// *************************************************************************** *
// *                                                                           *
// *                      Mentor Graphics Corporation                          *
// *                          All rights reserved                              *
// *                                                                           *
// *************************************************************************** *
// *                                                                           *
// * Description:         CANDB File                                           *
// * Generated at:        2021-02-26 13:32                                     *
// * System:              SPA4710_Final2                                       *
// * Variant:             ConfigurationsSPA3AD                                 *
// * Network:             Mid3Can                                              *
// *                                                                           *
// *************************************************************************** *
// *                                                                           *
// *             THIS CONFIGURATION MIGHT CONTAIN SOME ERRORS                  *
// *              IF THE INPUT MODEL WAS NOT PROPERLY FORMED!                  *
// *                    Do Not Use this File directly!                         *
// *                                                                           *
// *************************************************************************** *
VERSION "Mid3Can"

NS_ :

BS_ :

BU_ :  ETC SSM VCU1 VIM VIMB

BO_ 1120 VCU1Mid3CanFr14 : 8 VCU1
 SG_ CllsnAidSnvtySeld_UB : 20|1@0+ (1,0) [0|1] "" VIM,VIMB
 SG_ CllsnAidSnvtySeldPen : 35|4@0+ (1,0) [0|15] "" VIM,VIMB
 SG_ CllsnAidSnvtySeldSts : 37|2@0+ (1,0) [0|3] "" VIM,VIMB
 SG_ CllsnFwdWarnReq : 45|1@0+ (1,0) [0|1] "" VIM,VIMB
 SG_ CllsnFwdWarnReq_UB : 46|1@0+ (1,0) [0|1] "" VIM,VIMB
 SG_ CllsnThreat : 39|2@0+ (1,0) [0|3] "" VIM,VIMB
 SG_ CllsnThreat_UB : 47|1@0+ (1,0) [0|1] "" VIM,VIMB
 SG_ CnclReqForCrsCtrl : 22|2@0+ (1,0) [0|3] "" VIM,VIMB
 SG_ CnclReqForCrsCtrl_UB : 23|1@0+ (1,0) [0|1] "" VIM,VIMB
 SG_ CooltFlowInDtElecForExt : 1|10@0+ (0.01,0.0) [0.0|10.23] "L / min" VIM,VIMB
 SG_ CooltFlowInDtElecForExt_UB : 2|1@0+ (1,0) [0|1] "" VIM,VIMB
 SG_ CooltTInDtElecForExt : 18|11@0+ (0.1,-40.0) [-40.0|140.0] "degC" VIM,VIMB
 SG_ CooltTInDtElecForExt_UB : 3|1@0+ (1,0) [0|1] "" VIM,VIMB
 SG_ IndcrDisp1WdSts : 5|2@0+ (1,0) [0|3] "" VIM,VIMB
 SG_ IndcrDisp1WdSts_UB : 6|1@0+ (1,0) [0|1] "" VIM,VIMB
 SG_ IndcrTurnSts1WdSts : 43|2@0+ (1,0) [0|3] "" VIM
 SG_ IndcrTurnSts1WdSts_UB : 44|1@0+ (1,0) [0|1] "" VIM
 SG_ SrvRqrdForCllsnAid : 19|1@0+ (1,0) [0|1] "" VIM,VIMB
 SG_ SrvRqrdForCllsnAid_UB : 7|1@0+ (1,0) [0|1] "" VIM,VIMB

BO_ 1084 VCU1Mid3CanFr15 : 8 VCU1
 SG_ BeamHiIndcnDisp : 10|1@0+ (1,0) [0|1] "" VIM,VIMB
 SG_ BeamHiIndcnDisp_UB : 11|1@0+ (1,0) [0|1] "" VIM,VIMB
 SG_ BltLockStAtRowSecMid_UB : 3|1@0+ (1,0) [0|1] "" VIM,VIMB
 SG_ BltLockStAtRowSecMidForBltLockEquid : 2|1@0+ (1,0) [0|1] "" VIM,VIMB
 SG_ BltLockStAtRowSecMidForBltLockSt1 : 1|1@0+ (1,0) [0|1] "" VIM,VIMB
 SG_ BltLockStAtRowSecMidForBltLockSts : 0|1@0+ (1,0) [0|1] "" VIM,VIMB
 SG_ FltIndcrTurnLeFrnt : 24|1@0+ (1,0) [0|1] "" VIM,VIMB
 SG_ FltIndcrTurnLeFrnt_UB : 25|1@0+ (1,0) [0|1] "" VIM,VIMB
 SG_ FltIndcrTurnLeRe : 38|1@0+ (1,0) [0|1] "" VIM,VIMB
 SG_ FltIndcrTurnLeRe_UB : 39|1@0+ (1,0) [0|1] "" VIM,VIMB
 SG_ FltIndcrTurnRiFrnt : 36|1@0+ (1,0) [0|1] "" VIM,VIMB
 SG_ FltIndcrTurnRiFrnt_UB : 37|1@0+ (1,0) [0|1] "" VIM,VIMB
 SG_ FltIndcrTurnRiRe : 34|1@0+ (1,0) [0|1] "" VIM,VIMB
 SG_ FltIndcrTurnRiRe_UB : 35|1@0+ (1,0) [0|1] "" VIM,VIMB
 SG_ FltLiRvsg : 60|1@0+ (1,0) [0|1] "" VIM,VIMB
 SG_ FltLiRvsg_UB : 61|1@0+ (1,0) [0|1] "" VIM,VIMB
 SG_ FltOfBeamHiLe : 42|1@0+ (1,0) [0|1] "" VIM,VIMB
 SG_ FltOfBeamHiLe_UB : 43|1@0+ (1,0) [0|1] "" VIM,VIMB
 SG_ FltOfBeamHiRi : 40|1@0+ (1,0) [0|1] "" VIM,VIMB
 SG_ FltOfBeamHiRi_UB : 41|1@0+ (1,0) [0|1] "" VIM,VIMB
 SG_ FltOfBeamLoLe : 54|1@0+ (1,0) [0|1] "" VIM,VIMB
 SG_ FltOfBeamLoLe_UB : 55|1@0+ (1,0) [0|1] "" VIM,VIMB
 SG_ FltOfBeamLoRi : 52|1@0+ (1,0) [0|1] "" VIM,VIMB
 SG_ FltOfBeamLoRi_UB : 53|1@0+ (1,0) [0|1] "" VIM,VIMB
 SG_ FltOfBrkLiHiMntd : 30|1@0+ (1,0) [0|1] "" VIM,VIMB
 SG_ FltOfBrkLiHiMntd_UB : 31|1@0+ (1,0) [0|1] "" VIM,VIMB
 SG_ FltOfBrkLiLe : 28|1@0+ (1,0) [0|1] "" VIM,VIMB
 SG_ FltOfBrkLiLe_UB : 29|1@0+ (1,0) [0|1] "" VIM,VIMB
 SG_ FltOfBrkLiRi : 26|1@0+ (1,0) [0|1] "" VIM,VIMB
 SG_ FltOfBrkLiRi_UB : 27|1@0+ (1,0) [0|1] "" VIM,VIMB
 SG_ FltOfFogLiFrnt : 44|1@0+ (1,0) [0|1] "" VIM,VIMB
 SG_ FltOfFogLiFrnt_UB : 45|1@0+ (1,0) [0|1] "" VIM,VIMB
 SG_ FltOfLiPosnFrntLe : 32|1@0+ (1,0) [0|1] "" VIM,VIMB
 SG_ FltOfLiPosnFrntLe_UB : 33|1@0+ (1,0) [0|1] "" VIM,VIMB
 SG_ FltOfLiPosnFrntRi : 46|1@0+ (1,0) [0|1] "" VIM,VIMB
 SG_ FltOfLiPosnFrntRi_UB : 47|1@0+ (1,0) [0|1] "" VIM,VIMB
 SG_ FltOfPlateNr : 62|1@0+ (1,0) [0|1] "" VIM,VIMB
 SG_ FltOfPlateNr_UB : 63|1@0+ (1,0) [0|1] "" VIM,VIMB
 SG_ FltOfPosnReLe : 50|1@0+ (1,0) [0|1] "" VIM,VIMB
 SG_ FltOfPosnReLe_UB : 51|1@0+ (1,0) [0|1] "" VIM,VIMB
 SG_ FltOfPosnReRi : 48|1@0+ (1,0) [0|1] "" VIM,VIMB
 SG_ FltOfPosnReRi_UB : 49|1@0+ (1,0) [0|1] "" VIM,VIMB
 SG_ HdlampSysFailr : 58|1@0+ (1,0) [0|1] "" VIM,VIMB
 SG_ HdlampSysFailr_UB : 59|1@0+ (1,0) [0|1] "" VIM,VIMB
 SG_ SysBrkLiFailr : 12|1@0+ (1,0) [0|1] "" VIM,VIMB
 SG_ SysBrkLiFailr_UB : 13|1@0+ (1,0) [0|1] "" VIM,VIMB
 SG_ SysDirIndcnFailr : 14|1@0+ (1,0) [0|1] "" VIM,VIMB
 SG_ SysDirIndcnFailr_UB : 15|1@0+ (1,0) [0|1] "" VIM,VIMB
 SG_ TireRdEstimd : 9|10@0+ (0.00048828,0.25) [0.25|0.50048764] "m" SSM
 SG_ TireRdEstimd_UB : 4|1@0+ (1,0) [0|1] "" SSM
 SG_ TireRdEstimdQly : 6|2@0+ (1,0) [0|3] "" SSM
 SG_ TireRdEstimdQly_UB : 7|1@0+ (1,0) [0|1] "" SSM

BO_ 512 VCU1Mid3CanFr16 : 8 VCU1
 SG_ AsySftyDecelEnadByVehDyn : 62|1@0+ (1,0) [0|1] "" VIM,VIMB
 SG_ AsySftyDecelEnadByVehDyn_UB : 63|1@0+ (1,0) [0|1] "" VIM,VIMB
 SG_ EngOilPWarn : 5|1@0+ (1,0) [0|1] "" VIM,VIMB
 SG_ EngOilPWarn_UB : 6|1@0+ (1,0) [0|1] "" VIM,VIMB
 SG_ InhbOfAsySftyDecelByVehDyn : 60|1@0+ (1,0) [0|1] "" VIM,VIMB
 SG_ InhbOfAsySftyDecelByVehDyn_UB : 61|1@0+ (1,0) [0|1] "" VIM,VIMB
 SG_ PrpsnErrIndcnReq : 49|2@0+ (1,0) [0|3] "" VIM,VIMB
 SG_ PrpsnErrIndcnReq_UB : 7|1@0+ (1,0) [0|1] "" VIM,VIMB
 SG_ RoadLoadNom_UB : 4|1@0+ (1,0) [0|1] "" SSM
 SG_ RoadLoadNomCoeff0 : 2|11@0+ (1.0,0.0) [0.0|2047.0] "N" SSM
 SG_ RoadLoadNomCoeff1 : 17|10@0- (0.05859,0.0) [-29.8809|29.939490000000003] "Ns/m" SSM
 SG_ RoadLoadNomCoeff2 : 33|10@0+ (0.002929,0.0) [0.0|2.902639] "Ns^2/m^2" SSM
 SG_ RoadLoadNomCoeffSts : 3|1@0+ (1,0) [0|1] "" SSM
 SG_ TankFlapSts : 57|2@0+ (1,0) [0|3] "" VIM,VIMB
 SG_ TankFlapSts_UB : 58|1@0+ (1,0) [0|1] "" VIM,VIMB
 SG_ TrsmFltIndcn : 54|5@0+ (1,0) [0|31] "" VIM,VIMB
 SG_ TrsmFltIndcn_UB : 55|1@0+ (1,0) [0|1] "" VIM,VIMB

BO_ 384 VCU1Mid3CanFr17 : 8 VCU1
 SG_ ALnchTiDly3_UB : 47|1@0+ (1,0) [0|1] "" VIM,VIMB
 SG_ ALnchTiDly3Qf : 39|2@0+ (1,0) [0|3] "" VIM,VIMB
 SG_ ALnchTiDly3Sec2 : 37|6@0+ (0.1,0.0) [0.0|6.0] "s" VIM,VIMB
 SG_ AlrmSt : 9|2@0+ (1,0) [0|3] "" VIM,VIMB
 SG_ AlrmSts1_UB : 1|1@0+ (1,0) [0|1] "" VIM,VIMB
 SG_ AlrmTrgSrc : 13|4@0+ (1,0) [0|15] "" VIM,VIMB
 SG_ DoorDrvrReSts : 17|2@0+ (1,0) [0|3] "" SSM,VIM,VIMB
 SG_ DoorDrvrReSts_UB : 18|1@0+ (1,0) [0|1] "" SSM,VIM,VIMB
 SG_ DoorDrvrSts : 20|2@0+ (1,0) [0|3] "" SSM,VIM,VIMB
 SG_ DoorDrvrSts_UB : 21|1@0+ (1,0) [0|1] "" SSM,VIM,VIMB
 SG_ DoorPassReSts : 31|2@0+ (1,0) [0|3] "" SSM,VIM,VIMB
 SG_ DoorPassReSts_UB : 22|1@0+ (1,0) [0|1] "" SSM,VIM,VIMB
 SG_ DoorPassSts : 29|2@0+ (1,0) [0|3] "" SSM,VIM,VIMB
 SG_ DoorPassSts_UB : 23|1@0+ (1,0) [0|1] "" SSM,VIM,VIMB
 SG_ EngOilLvlSts : 7|3@0+ (1,0) [0|7] "" VIM,VIMB
 SG_ EngOilLvlSts_UB : 4|1@0+ (1,0) [0|1] "" VIM,VIMB
 SG_ HoodSts : 27|2@0+ (1,0) [0|3] "" VIM,VIMB
 SG_ HoodSts_UB : 2|1@0+ (1,0) [0|1] "" VIM,VIMB
 SG_ SnsrInclnFailr : 14|1@0+ (1,0) [0|1] "" VIM,VIMB
 SG_ SnsrIntrScanrFailr : 15|1@0+ (1,0) [0|1] "" VIM,VIMB
 SG_ SnsrSoundrBattBackedFailr : 0|1@0+ (1,0) [0|1] "" VIM,VIMB
 SG_ TrSts : 25|2@0+ (1,0) [0|3] "" SSM,VIM,VIMB
 SG_ TrSts_UB : 3|1@0+ (1,0) [0|1] "" SSM,VIM,VIMB

BO_ 119 VCU1Mid3CanFr18 : 8 VCU1
 SG_ AccrPedlPsd_UB : 9|1@0+ (1,0) [0|1] "" VIM,VIMB
 SG_ AccrPedlPsdAccrPedlPsd : 11|1@0+ (1,0) [0|1] "" VIM,VIMB
 SG_ AccrPedlPsdAccrPedlPsdChks : 7|8@0+ (1.0,0.0) [0.0|255.0] "Unitless" VIM,VIMB
 SG_ AccrPedlPsdAccrPedlPsdCntr : 15|4@0+ (1.0,0.0) [0.0|15.0] "Unitless" VIM,VIMB
 SG_ AccrPedlPsdAccrPedlPsdSts : 10|1@0+ (1,0) [0|1] "" VIM,VIMB
 SG_ AsySftyBrkDlyEstimd : 22|7@0+ (0.01,0.0) [0.0|1.27] "s" VIM,VIMB
 SG_ AsySftyBrkDlyEstimd_UB : 23|1@0+ (1,0) [0|1] "" VIM,VIMB
 SG_ BrkPedlNotPsdSafe : 31|1@0+ (1,0) [0|1] "" VIM,VIMB
 SG_ BrkPedlPsd : 30|1@0+ (1,0) [0|1] "" VIM,VIMB
 SG_ BrkPedlPsdChks : 39|8@0+ (1.0,0.0) [0.0|255.0] "Unitless" VIM,VIMB
 SG_ BrkPedlPsdCntr : 27|4@0+ (1.0,0.0) [0.0|15.0] "Unitless" VIM,VIMB
 SG_ BrkPedlPsdQf : 29|2@0+ (1,0) [0|3] "" VIM,VIMB
 SG_ BrkPedlPsdSafeGroup_UB : 8|1@0+ (1,0) [0|1] "" VIM,VIMB
 SG_ HvSysActvStsExt1 : 46|1@0+ (1,0) [0|1] "" VIM,VIMB
 SG_ HvSysActvStsExt1_UB : 47|1@0+ (1,0) [0|1] "" VIM,VIMB
 SG_ OvrdDecelByDrvr_UB : 45|1@0+ (1,0) [0|1] "" VIM,VIMB
 SG_ OvrdDecelByDrvrOvrdDecelByDrvr : 44|1@0+ (1,0) [0|1] "" VIM,VIMB
 SG_ OvrdDecelByDrvrOvrdDecelByDrvrChks : 55|8@0+ (1.0,0.0) [0.0|255.0] "Unitless" VIM,VIMB
 SG_ OvrdDecelByDrvrOvrdDecelByDrvrCntr : 43|4@0+ (1.0,0.0) [0.0|15.0] "Unitless" VIM,VIMB

BO_ 104 VCU1Mid3CanFr19 : 8 VCU1
 SG_ AccrPedlRat : 6|15@0+ (0.00390625,0.0) [0.0|100.0] "%" VIM,VIMB
 SG_ AccrPedlRat_UB : 7|1@0+ (1,0) [0|1] "" VIM,VIMB
 SG_ ChrgnUReqExt : 31|8@0+ (0.025,10.6) [10.6|16.0] "Volt" VIM,VIMB
 SG_ ChrgnUReqExt_UB : 59|1@0+ (1,0) [0|1] "" VIM,VIMB
 SG_ DrvrDecelReq : 23|8@0- (0.1,0.0) [-12.8|12.700000000000001] "m/s^2" VIM,VIMB
 SG_ DrvrDecelReq_UB : 32|1@0+ (1,0) [0|1] "" VIM,VIMB
 SG_ PtGearAct : 46|4@0+ (1,0) [0|15] "" VIM,VIMB
 SG_ PtGearAct_UB : 47|1@0+ (1,0) [0|1] "" VIM,VIMB
 SG_ TirePWarnFrntRi_UB : 42|1@0+ (1,0) [0|1] "" VIM,VIMB
 SG_ TirePWarnFrntRiTirePWarn : 55|2@0+ (1,0) [0|3] "" VIM,VIMB
 SG_ TirePWarnFrntRiTirePWarnType : 53|2@0+ (1,0) [0|3] "" VIM,VIMB
 SG_ TirePWarnReLe_UB : 41|1@0+ (1,0) [0|1] "" VIM,VIMB
 SG_ TirePWarnReLeTirePWarn : 51|2@0+ (1,0) [0|3] "" VIM,VIMB
 SG_ TirePWarnReLeTirePWarnType : 49|2@0+ (1,0) [0|3] "" VIM,VIMB
 SG_ TirePWarnReRi_UB : 40|1@0+ (1,0) [0|1] "" VIM,VIMB
 SG_ TirePWarnReRiTirePWarn : 63|2@0+ (1,0) [0|3] "" VIM,VIMB
 SG_ TirePWarnReRiTirePWarnType : 61|2@0+ (1,0) [0|3] "" VIM,VIMB

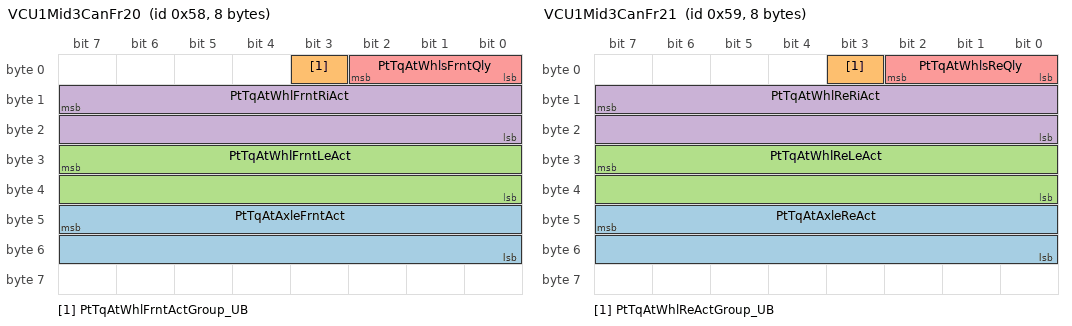
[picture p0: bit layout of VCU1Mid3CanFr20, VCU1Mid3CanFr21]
BO_ 88 VCU1Mid3CanFr20 : 8 VCU1
 SG_ PtTqAtAxleFrntAct : 47|16@0- (1.0,0.0) [-20000.0|20000.0] "NewtonMeter" VIM,VIMB
 SG_ PtTqAtWhlFrntActGroup_UB : 3|1@0+ (1,0) [0|1] "" VIM,VIMB
 SG_ PtTqAtWhlFrntLeAct : 31|16@0- (1.0,0.0) [-20000.0|20000.0] "NewtonMeter" VIM,VIMB
 SG_ PtTqAtWhlFrntRiAct : 15|16@0- (1.0,0.0) [-20000.0|20000.0] "NewtonMeter" VIM,VIMB
 SG_ PtTqAtWhlsFrntQly : 2|3@0+ (1,0) [0|7] "" VIM,VIMB

BO_ 89 VCU1Mid3CanFr21 : 8 VCU1
 SG_ PtTqAtAxleReAct : 47|16@0- (1.0,0.0) [-20000.0|20000.0] "NewtonMeter" VIM,VIMB
 SG_ PtTqAtWhlReActGroup_UB : 3|1@0+ (1,0) [0|1] "" VIM,VIMB
 SG_ PtTqAtWhlReLeAct : 31|16@0- (1.0,0.0) [-20000.0|20000.0] "NewtonMeter" VIM,VIMB
 SG_ PtTqAtWhlReRiAct : 15|16@0- (1.0,0.0) [-20000.0|20000.0] "NewtonMeter" VIM,VIMB
 SG_ PtTqAtWhlsReQly : 2|3@0+ (1,0) [0|7] "" VIM,VIMB

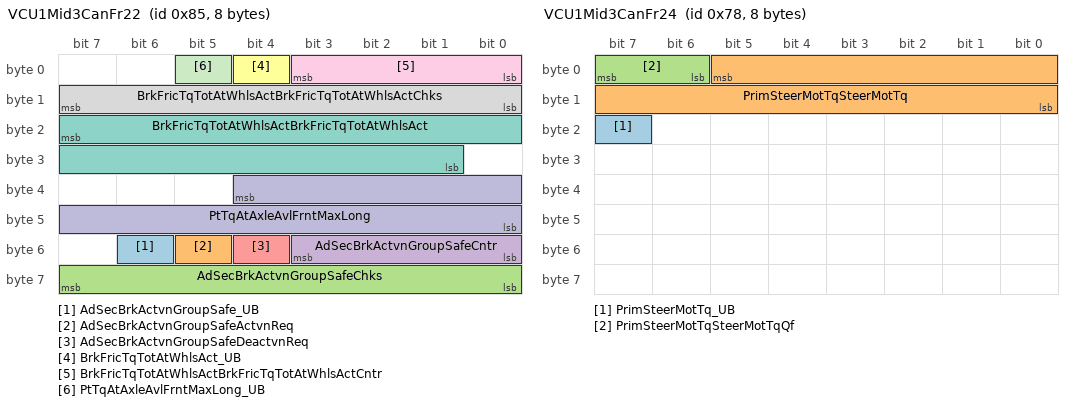
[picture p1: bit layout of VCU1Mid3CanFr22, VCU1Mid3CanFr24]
BO_ 133 VCU1Mid3CanFr22 : 8 VCU1
 SG_ AdSecBrkActvnGroupSafe_UB : 54|1@0+ (1,0) [0|1] "" SSM
 SG_ AdSecBrkActvnGroupSafeActvnReq : 53|1@0+ (1,0) [0|1] "" SSM
 SG_ AdSecBrkActvnGroupSafeChks : 63|8@0+ (1.0,0.0) [0.0|255.0] "Unitless" SSM
 SG_ AdSecBrkActvnGroupSafeCntr : 51|4@0+ (1.0,0.0) [0.0|15.0] "Unitless" SSM
 SG_ AdSecBrkActvnGroupSafeDeactvnReq : 52|1@0+ (1,0) [0|1] "" SSM
 SG_ BrkFricTqTotAtWhlsAct_UB : 4|1@0+ (1,0) [0|1] "" VIM,VIMB
 SG_ BrkFricTqTotAtWhlsActBrkFricTqTotAtWhlsAct : 23|15@0+ (1.0,0.0) [0.0|20000.0] "NewtonMeter" VIM,VIMB
 SG_ BrkFricTqTotAtWhlsActBrkFricTqTotAtWhlsActChks : 15|8@0+ (1.0,0.0) [0.0|255.0] "Unitless" VIM,VIMB
 SG_ BrkFricTqTotAtWhlsActBrkFricTqTotAtWhlsActCntr : 3|4@0+ (1.0,0.0) [0.0|15.0] "Unitless" VIM,VIMB
 SG_ PtTqAtAxleAvlFrntMaxLong : 36|13@0- (4.0,0.0) [-16384.0|16380.0] "NewtonMeter" VIM,VIMB
 SG_ PtTqAtAxleAvlFrntMaxLong_UB : 5|1@0+ (1,0) [0|1] "" VIM,VIMB

BO_ 352 VCU1Mid3CanFr23 : 8 VCU1
 SG_ TirePMonSysFlt : 6|3@0+ (1,0) [0|7] "" VIM,VIMB
 SG_ TirePMonSysFlt_UB : 7|1@0+ (1,0) [0|1] "" VIM,VIMB
 SG_ TirePValFrntLe_UB : 3|1@0+ (1,0) [0|1] "" SSM,VIM,VIMB
 SG_ TirePValFrntLeTirepabsltVal1 : 15|8@0+ (2.5,0.0) [0.0|637.5] "hPa" SSM,VIM,VIMB
 SG_ TirePValFrntLeTirePabsltValQF : 1|2@0+ (1,0) [0|3] "" SSM,VIM,VIMB
 SG_ TirePValFrntLeTirePPosn : 2|1@0+ (1,0) [0|1] "" SSM,VIM,VIMB
 SG_ TirePValFrntRi_UB : 19|1@0+ (1,0) [0|1] "" SSM,VIM,VIMB
 SG_ TirePValFrntRiTirePAbsltVal1 : 31|8@0+ (2.5,0.0) [0.0|637.5] "hPa" SSM,VIM,VIMB
 SG_ TirePValFrntRiTirePAbsltValQF : 17|2@0+ (1,0) [0|3] "" SSM,VIM,VIMB
 SG_ TirePValFrntRiTirePPosn : 18|1@0+ (1,0) [0|1] "" SSM,VIM,VIMB
 SG_ TirePValReLe_UB : 20|1@0+ (1,0) [0|1] "" SSM,VIM,VIMB
 SG_ TirePValReLeTirePAbsltVal1 : 47|8@0+ (2.5,0.0) [0.0|637.5] "hPa" SSM,VIM,VIMB
 SG_ TirePValReLeTirePAbsltValQF : 33|2@0+ (1,0) [0|3] "" SSM,VIM,VIMB
 SG_ TirePValReLeTirePPosn : 34|1@0+ (1,0) [0|1] "" SSM,VIM,VIMB
 SG_ TirePValReRi_UB : 21|1@0+ (1,0) [0|1] "" SSM,VIM,VIMB
 SG_ TirePValReRiTirePAbsltVal1 : 63|8@0+ (2.5,0.0) [0.0|637.5] "hPa" SSM,VIM,VIMB
 SG_ TirePValReRiTirePAbsltValQF : 49|2@0+ (1,0) [0|3] "" SSM,VIM,VIMB
 SG_ TirePValReRiTirePPosn : 50|1@0+ (1,0) [0|1] "" SSM,VIM,VIMB
 SG_ TirePWarnCmn_UB : 39|1@0+ (1,0) [0|1] "" VIM,VIMB
 SG_ TirePWarnCmnTirePWarn : 38|2@0+ (1,0) [0|3] "" VIM,VIMB
 SG_ TirePWarnCmnTirePWarnType : 36|2@0+ (1,0) [0|3] "" VIM,VIMB
 SG_ TirePWarnFrntLe_UB : 55|1@0+ (1,0) [0|1] "" VIM,VIMB
 SG_ TirePWarnFrntLeTirePWarn : 54|2@0+ (1,0) [0|3] "" VIM,VIMB
 SG_ TirePWarnFrntLeTirePWarnType : 52|2@0+ (1,0) [0|3] "" VIM,VIMB

BO_ 120 VCU1Mid3CanFr24 : 8 VCU1
 SG_ PrimSteerMotTq_UB : 23|1@0+ (1,0) [0|1] "" VIM
 SG_ PrimSteerMotTqSteerMotTq : 5|14@0- (0.00390625,0.0) [-30.0|30.0] "NewtonMeter" VIM
 SG_ PrimSteerMotTqSteerMotTqQf : 7|2@0+ (1,0) [0|3] "" VIM

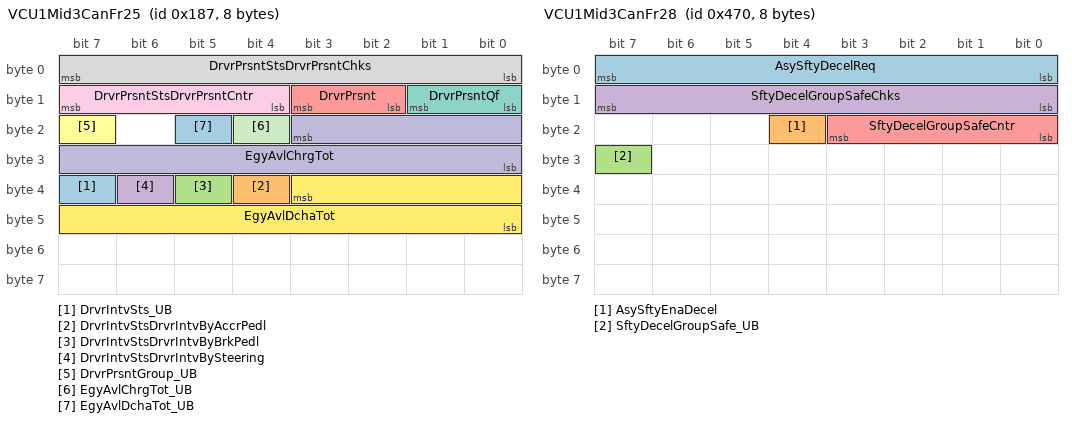
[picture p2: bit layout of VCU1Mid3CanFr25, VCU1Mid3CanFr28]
BO_ 391 VCU1Mid3CanFr25 : 8 VCU1
 SG_ DrvrIntvSts_UB : 39|1@0+ (1,0) [0|1] "" VIM,VIMB
 SG_ DrvrIntvStsDrvrIntvByAccrPedl : 36|1@0+ (1,0) [0|1] "" VIM,VIMB
 SG_ DrvrIntvStsDrvrIntvByBrkPedl : 37|1@0+ (1,0) [0|1] "" VIM,VIMB
 SG_ DrvrIntvStsDrvrIntvBySteering : 38|1@0+ (1,0) [0|1] "" VIM,VIMB
 SG_ DrvrPrsnt : 11|2@0+ (1,0) [0|3] "" VIM,VIMB
 SG_ DrvrPrsntGroup_UB : 23|1@0+ (1,0) [0|1] "" VIM,VIMB
 SG_ DrvrPrsntQf : 9|2@0+ (1,0) [0|3] "" VIM,VIMB
 SG_ DrvrPrsntStsDrvrPrsntChks : 7|8@0+ (1.0,0.0) [0.0|255.0] "Unitless" VIM,VIMB
 SG_ DrvrPrsntStsDrvrPrsntCntr : 15|4@0+ (1.0,0.0) [0.0|15.0] "Unitless" VIM,VIMB
 SG_ EgyAvlChrgTot : 19|12@0+ (50.0,-500.0) [-500.0|120000.0] "Wh" VIM,VIMB
 SG_ EgyAvlChrgTot_UB : 20|1@0+ (1,0) [0|1] "" VIM,VIMB
 SG_ EgyAvlDchaTot : 35|12@0+ (50.0,-500.0) [-500.0|120000.0] "Wh" VIM,VIMB
 SG_ EgyAvlDchaTot_UB : 21|1@0+ (1,0) [0|1] "" VIM,VIMB

BO_ 1136 VCU1Mid3CanFr28 : 8 VCU1
 SG_ AsySftyDecelReq : 7|8@0+ (0.1,0.0) [0.0|15.0] "Unitless" VIM,VIMB
 SG_ AsySftyEnaDecel : 20|1@0+ (1,0) [0|1] "" VIM,VIMB
 SG_ SftyDecelGroupSafe_UB : 31|1@0+ (1,0) [0|1] "" VIM,VIMB
 SG_ SftyDecelGroupSafeChks : 15|8@0+ (1.0,0.0) [0.0|255.0] "Unitless" VIM,VIMB
 SG_ SftyDecelGroupSafeCntr : 19|4@0+ (1.0,0.0) [0.0|15.0] "Unitless" VIM,VIMB

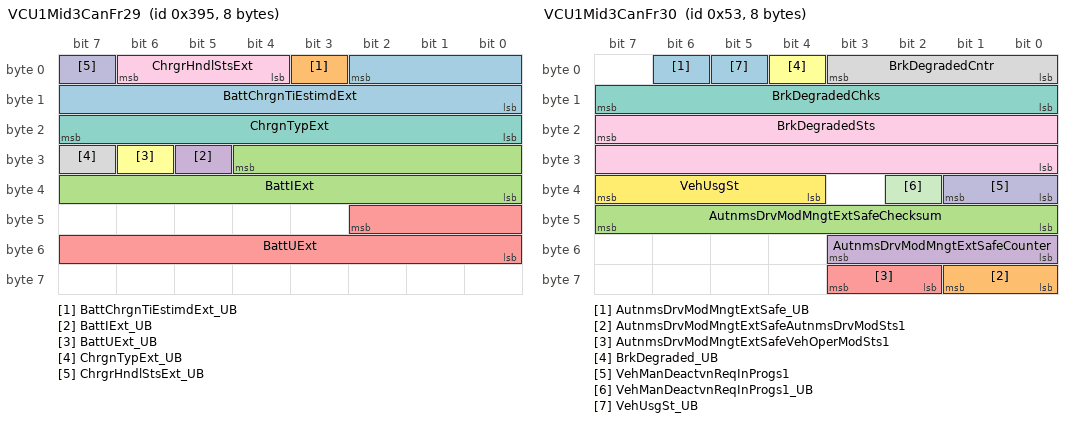
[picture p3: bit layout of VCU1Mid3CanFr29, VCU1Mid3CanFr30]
BO_ 917 VCU1Mid3CanFr29 : 8 VCU1
 SG_ BattChrgnTiEstimdExt : 2|11@0+ (1.0,0.0) [0.0|2047.0] "Mins" VIM,VIMB
 SG_ BattChrgnTiEstimdExt_UB : 3|1@0+ (1,0) [0|1] "" VIM,VIMB
 SG_ BattIExt : 28|13@0+ (0.1,-410.0) [-410.0|409.1] "A" VIM,VIMB
 SG_ BattIExt_UB : 29|1@0+ (1,0) [0|1] "" VIM,VIMB
 SG_ BattUExt : 42|11@0+ (0.25,0.0) [0.0|511.0] "Volt" VIM,VIMB
 SG_ BattUExt_UB : 30|1@0+ (1,0) [0|1] "" VIM,VIMB
 SG_ ChrgnTypExt : 23|8@0+ (1,0) [0|255] "" VIM,VIMB
 SG_ ChrgnTypExt_UB : 31|1@0+ (1,0) [0|1] "" VIM,VIMB
 SG_ ChrgrHndlStsExt : 6|3@0+ (1,0) [0|7] "" VIM,VIMB
 SG_ ChrgrHndlStsExt_UB : 7|1@0+ (1,0) [0|1] "" VIM,VIMB

BO_ 83 VCU1Mid3CanFr30 : 8 VCU1
 SG_ AutnmsDrvModMngtExtSafe_UB : 6|1@0+ (1,0) [0|1] "" VIM,VIMB
 SG_ AutnmsDrvModMngtExtSafeAutnmsDrvModSts1 : 56|2@1+ (1,0) [0|3] "" VIM,VIMB
 SG_ AutnmsDrvModMngtExtSafeChecksum : 40|8@1+ (1.0,0.0) [0.0|255.0] "Unitless" VIM,VIMB
 SG_ AutnmsDrvModMngtExtSafeCounter : 48|4@1+ (1.0,0.0) [0.0|15.0] "Unitless" VIM,VIMB
 SG_ AutnmsDrvModMngtExtSafeVehOperModSts1 : 58|2@1+ (1,0) [0|3] "" VIM,VIMB
 SG_ BrkDegraded_UB : 4|1@0+ (1,0) [0|1] "" VIM,VIMB
 SG_ BrkDegradedChks : 15|8@0+ (1.0,0.0) [0.0|255.0] "Unitless" VIM,VIMB
 SG_ BrkDegradedCntr : 3|4@0+ (1.0,0.0) [0.0|15.0] "Unitless" VIM,VIMB
 SG_ BrkDegradedSts : 23|16@0+ (1.0,0.0) [0.0|65535.0] "Unitless" VIM,VIMB
 SG_ VehManDeactvnReqInProgs1 : 33|2@0+ (1,0) [0|3] "" VIM,VIMB
 SG_ VehManDeactvnReqInProgs1_UB : 34|1@0+ (1,0) [0|1] "" VIM,VIMB
 SG_ VehUsgSt : 39|4@0+ (1,0) [0|15] "" VIM,VIMB
 SG_ VehUsgSt_UB : 5|1@0+ (1,0) [0|1] "" VIM,VIMB

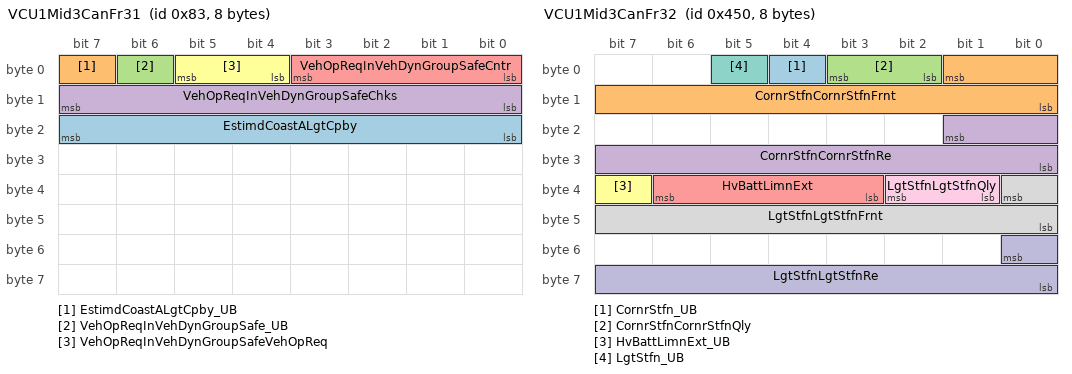
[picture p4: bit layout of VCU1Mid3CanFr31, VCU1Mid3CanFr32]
BO_ 131 VCU1Mid3CanFr31 : 8 VCU1
 SG_ EstimdCoastALgtCpby : 23|8@0+ (0.1,-3.0) [-3.0|15.0] "m/s^2" VIM,VIMB
 SG_ EstimdCoastALgtCpby_UB : 7|1@0+ (1,0) [0|1] "" VIM,VIMB
 SG_ VehOpReqInVehDynGroupSafe_UB : 6|1@0+ (1,0) [0|1] "" SSM
 SG_ VehOpReqInVehDynGroupSafeChks : 15|8@0+ (1.0,0.0) [0.0|255.0] "Unitless" SSM
 SG_ VehOpReqInVehDynGroupSafeCntr : 3|4@0+ (1.0,0.0) [0.0|15.0] "Unitless" SSM
 SG_ VehOpReqInVehDynGroupSafeVehOpReq : 5|2@0+ (1,0) [0|3] "" SSM

BO_ 1104 VCU1Mid3CanFr32 : 8 VCU1
 SG_ CornrStfn_UB : 4|1@0+ (1,0) [0|1] "" SSM
 SG_ CornrStfnCornrStfnFrnt : 1|10@0+ (390.625,0.0) [0.0|399609.375] "N" SSM
 SG_ CornrStfnCornrStfnQly : 3|2@0+ (1,0) [0|3] "" SSM
 SG_ CornrStfnCornrStfnRe : 17|10@0+ (390.625,0.0) [0.0|399609.375] "N" SSM
 SG_ HvBattLimnExt : 38|4@0+ (1,0) [0|15] "" VIM
 SG_ HvBattLimnExt_UB : 39|1@0+ (1,0) [0|1] "" VIM
 SG_ LgtStfn_UB : 5|1@0+ (1,0) [0|1] "" SSM
 SG_ LgtStfnLgtStfnFrnt : 32|9@0+ (0.5,0.0) [0.0|255.5] "Unitless" SSM
 SG_ LgtStfnLgtStfnQly : 34|2@0+ (1,0) [0|3] "" SSM
 SG_ LgtStfnLgtStfnRe : 48|9@0+ (0.5,0.0) [0.0|255.5] "Unitless" SSM

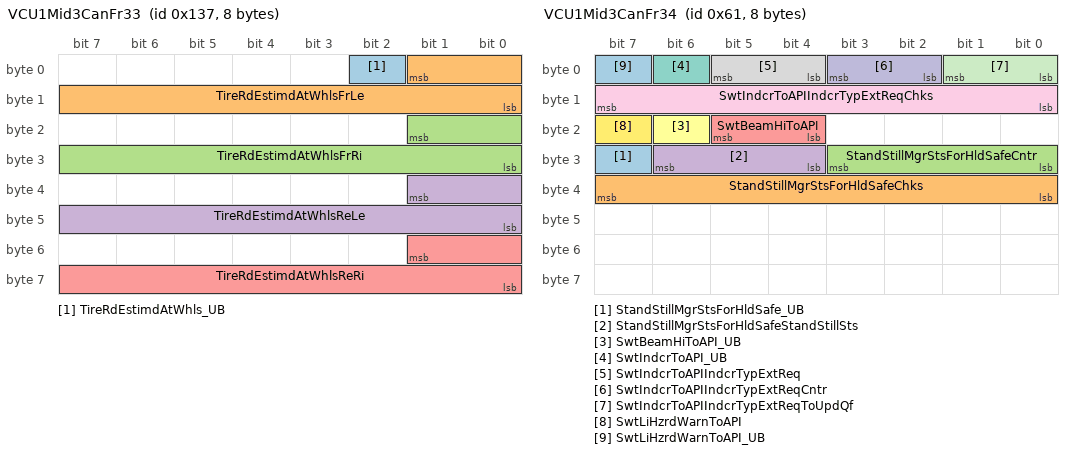
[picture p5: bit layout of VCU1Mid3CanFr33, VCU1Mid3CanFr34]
BO_ 311 VCU1Mid3CanFr33 : 8 VCU1
 SG_ TireRdEstimdAtWhls_UB : 2|1@0+ (1,0) [0|1] "" SSM
 SG_ TireRdEstimdAtWhlsFrLe : 1|10@0+ (0.00048828,0.25) [0.25|0.50048764] "m" SSM
 SG_ TireRdEstimdAtWhlsFrRi : 17|10@0+ (0.00048828,0.25) [0.25|0.50048764] "m" SSM
 SG_ TireRdEstimdAtWhlsReLe : 33|10@0+ (0.00048828,0.25) [0.25|0.50048764] "m" SSM
 SG_ TireRdEstimdAtWhlsReRi : 49|10@0+ (0.00048828,0.25) [0.25|0.50048764] "m" SSM

BO_ 97 VCU1Mid3CanFr34 : 8 VCU1
 SG_ StandStillMgrStsForHldSafe_UB : 31|1@0+ (1,0) [0|1] "" VIM,VIMB
 SG_ StandStillMgrStsForHldSafeChks : 39|8@0+ (1.0,0.0) [0.0|255.0] "Unitless" VIM,VIMB
 SG_ StandStillMgrStsForHldSafeCntr : 27|4@0+ (1.0,0.0) [0.0|15.0] "Unitless" VIM,VIMB
 SG_ StandStillMgrStsForHldSafeStandStillSts : 30|3@0+ (1,0) [0|7] "" VIM,VIMB
 SG_ SwtBeamHiToAPI : 21|2@0+ (1,0) [0|3] "" VIM,VIMB
 SG_ SwtBeamHiToAPI_UB : 22|1@0+ (1,0) [0|1] "" VIM,VIMB
 SG_ SwtIndcrToAPI_UB : 6|1@0+ (1,0) [0|1] "" VIM,VIMB
 SG_ SwtIndcrToAPIIndcrTypExtReq : 5|2@0+ (1,0) [0|3] "" VIM,VIMB
 SG_ SwtIndcrToAPIIndcrTypExtReqChks : 15|8@0+ (1.0,0.0) [0.0|255.0] "Unitless" VIM,VIMB
 SG_ SwtIndcrToAPIIndcrTypExtReqCntr : 3|2@0+ (1.0,0.0) [0.0|3.0] "Unitless" VIM,VIMB
 SG_ SwtIndcrToAPIIndcrTypExtReqToUpdQf : 1|2@0+ (1,0) [0|3] "" VIM,VIMB
 SG_ SwtLiHzrdWarnToAPI : 23|1@0+ (1,0) [0|1] "" VIM,VIMB
 SG_ SwtLiHzrdWarnToAPI_UB : 7|1@0+ (1,0) [0|1] "" VIM,VIMB

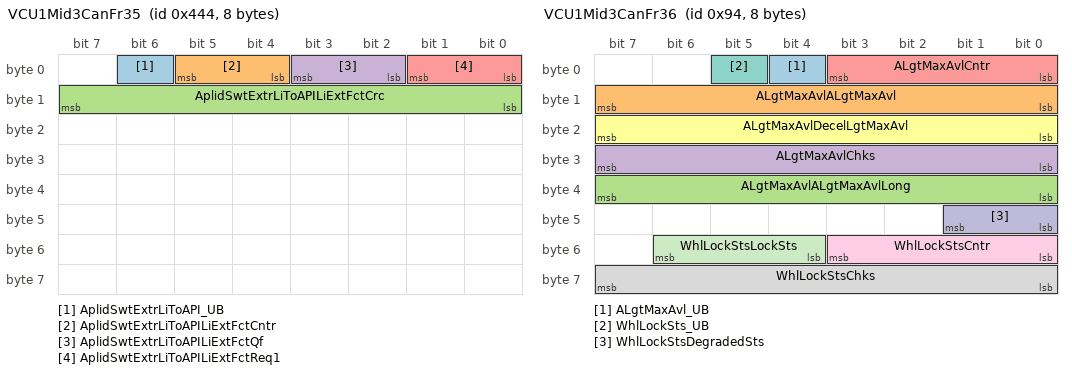
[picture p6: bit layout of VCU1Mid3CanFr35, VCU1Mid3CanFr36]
BO_ 1092 VCU1Mid3CanFr35 : 8 VCU1
 SG_ AplidSwtExtrLiToAPI_UB : 6|1@0+ (1,0) [0|1] "" VIM,VIMB
 SG_ AplidSwtExtrLiToAPILiExtFctCntr : 5|2@0+ (1.0,0.0) [0.0|3.0] "Unitless" VIM,VIMB
 SG_ AplidSwtExtrLiToAPILiExtFctCrc : 15|8@0+ (1.0,0.0) [0.0|255.0] "Unitless" VIM,VIMB
 SG_ AplidSwtExtrLiToAPILiExtFctQf : 3|2@0+ (1,0) [0|3] "" VIM,VIMB
 SG_ AplidSwtExtrLiToAPILiExtFctReq1 : 1|2@0+ (1,0) [0|3] "" VIM,VIMB

BO_ 148 VCU1Mid3CanFr36 : 8 VCU1
 SG_ ALgtMaxAvl_UB : 4|1@0+ (1,0) [0|1] "" VIM,VIMB
 SG_ ALgtMaxAvlALgtMaxAvl : 15|8@0+ (0.1,-3.0) [-3.0|15.0] "m/s^2" VIM,VIMB
 SG_ ALgtMaxAvlALgtMaxAvlLong : 39|8@0+ (0.1,-3.0) [-3.0|15.0] "m/s^2" VIM,VIMB
 SG_ ALgtMaxAvlChks : 31|8@0+ (1.0,0.0) [0.0|255.0] "Unitless" VIM,VIMB
 SG_ ALgtMaxAvlCntr : 3|4@0+ (1.0,0.0) [0.0|15.0] "Unitless" VIM,VIMB
 SG_ ALgtMaxAvlDecelLgtMaxAvl : 23|8@0+ (0.1,0.0) [0.0|15.0] "m/s^2" VIM,VIMB
 SG_ WhlLockSts_UB : 5|1@0+ (1,0) [0|1] "" VIM
 SG_ WhlLockStsChks : 63|8@0+ (1.0,0.0) [0.0|255.0] "Unitless" VIM
 SG_ WhlLockStsCntr : 51|4@0+ (1.0,0.0) [0.0|15.0] "Unitless" VIM
 SG_ WhlLockStsDegradedSts : 41|2@0+ (1,0) [0|3] "" VIM
 SG_ WhlLockStsLockSts : 54|3@0+ (1,0) [0|7] "" VIM

BO_ 1283 Vcu1Mid3CanNmFr : 8 VCU1
 SG_ Body_VCU1 : 21|1@0+ (1,0) [0|0] "" SSM
 SG_ Brake_VCU1 : 33|1@0+ (1,0) [0|0] "" SSM
 SG_ Diesel_VCU1 : 32|1@0+ (1,0) [0|0] "" SSM
 SG_ Hazard_VCU1 : 18|1@0+ (1,0) [0|0] "" SSM
 SG_ InfotainmentAndHMI_VCU1 : 22|1@0+ (1,0) [0|0] "" SSM
 SG_ PNCCharging_VCU1 : 25|1@0+ (1,0) [0|0] "" SSM
 SG_ PNCDriverinfo_VCU1 : 16|1@0+ (1,0) [0|0] "" SSM
 SG_ PNCDriverinfoPoll_VCU1 : 31|1@0+ (1,0) [0|0] "" SSM
 SG_ PNCDriving_VCU1 : 27|1@0+ (1,0) [0|0] "" SSM
 SG_ PNCEntrance_VCU1 : 23|1@0+ (1,0) [0|0] "" SSM
 SG_ PNCGlobal_VCU1 : 29|1@0+ (1,0) [0|0] "" SSM
 SG_ PNCGSD_VCU1 : 30|1@0+ (1,0) [0|0] "" SSM
 SG_ PNCHVEnergyStorage_VCU1 : 35|1@0+ (1,0) [0|0] "" SSM
 SG_ PNCLocking_VCU1 : 17|1@0+ (1,0) [0|0] "" SSM
 SG_ PNCPreClimatization_VCU1 : 26|1@0+ (1,0) [0|0] "" SSM
 SG_ PNCSpare1_VCU1 : 39|1@0+ (1,0) [0|0] "" SSM
 SG_ PNCSpare2_VCU1 : 38|1@0+ (1,0) [0|0] "" SSM
 SG_ PNCSpare3_VCU1 : 37|1@0+ (1,0) [0|0] "" SSM
 SG_ PNCSpare4_VCU1 : 36|1@0+ (1,0) [0|0] "" SSM
 SG_ PNCStart_VCU1 : 24|1@0+ (1,0) [0|0] "" SSM
 SG_ PNCTrailerCaravan_VCU1 : 28|1@0+ (1,0) [0|0] "" SSM
 SG_ VehicleAPI_VCU1 : 34|1@0+ (1,0) [0|0] "" SSM
 SG_ Visibility_VCU1 : 20|1@0+ (1,0) [0|0] "" SSM
 SG_ WarningSounds_VCU1 : 19|1@0+ (1,0) [0|0] "" SSM
 SG_ NM_PNI_VCU1 : 14|1@0+ (1,0) [0|0] "" SSM
 SG_ NM_AW_VCU1 : 12|1@0+ (1,0) [0|0] "" SSM
 SG_ NM_CS_VCU1 : 11|1@0+ (1,0) [0|0] "" SSM
 SG_ NM_RMR_VCU1 : 8|1@0+ (1,0) [0|0] "" SSM
 SG_ NM_NodeID_VCU1 : 7|8@0+ (1,0) [0|0] "" SSM

BO_ 2047 Vcu1ToAllFuncMid3DiagReqFrame : 8 VCU1
 SG_ Vcu1ToAllFuncMid3DiagReqNpdu : 7|64@0+ (1,0) [0|0] "" VIM

BO_ 84 VIMMid3CanFr01 : 8 VIM
 SG_ HornActvnReqIf : 22|1@0+ (1,0) [0|1] "" VCU1
 SG_ HornActvnReqIf_UB : 23|1@0+ (1,0) [0|1] "" VCU1
 SG_ HvSysActvReqExt : 4|1@0+ (1,0) [0|1] "" VCU1
 SG_ HvSysActvReqExt_UB : 5|1@0+ (1,0) [0|1] "" VCU1
 SG_ RainSnsrCmdIf : 8|1@0+ (1,0) [0|1] "" VCU1
 SG_ RainSnsrCmdIf_UB : 9|1@0+ (1,0) [0|1] "" VCU1
 SG_ SnsrClngReqIf_UB : 21|1@0+ (1,0) [0|1] "" VCU1
 SG_ SnsrClngReqIfClngProg : 31|4@0+ (1,0) [0|15] "" VCU1
 SG_ SnsrClngReqIfSnsrSeld : 27|4@0+ (1,0) [0|15] "" VCU1
 SG_ SwtBeamHiFromAPI : 7|2@0+ (1,0) [0|3] "" VCU1
 SG_ SwtBeamHiFromAPI_UB : 20|1@0+ (1,0) [0|1] "" VCU1
 SG_ WinWshngCmdIf : 15|2@0+ (1,0) [0|3] "" VCU1
 SG_ WinWshngCmdIf_UB : 0|1@0+ (1,0) [0|1] "" VCU1
 SG_ WipgSpdIntlIf : 13|3@0+ (1,0) [0|7] "" VCU1
 SG_ WipgSpdIntlIf_UB : 10|1@0+ (1,0) [0|1] "" VCU1
 SG_ WiprFrntReqIf_UB : 39|1@0+ (1,0) [0|1] "" VCU1
 SG_ WiprFrntReqIfFrntWiprLvrCmd1 : 34|3@0+ (1,0) [0|7] "" VCU1
 SG_ WiprFrntReqIfFrntWiprLvrCntr : 36|2@0+ (1.0,0.0) [0.0|3.0] "Unitless" VCU1
 SG_ WiprFrntReqIfFrntWiprLvrCrc : 47|8@0+ (1.0,0.0) [0.0|255.0] "Unitless" VCU1
 SG_ WiprFrntReqIfFrntWiprLvrQf : 38|2@0+ (1,0) [0|3] "" VCU1
 SG_ WiprReCmdIf : 2|2@0+ (1,0) [0|3] "" VCU1
 SG_ WiprReCmdIf_UB : 3|1@0+ (1,0) [0|1] "" VCU1

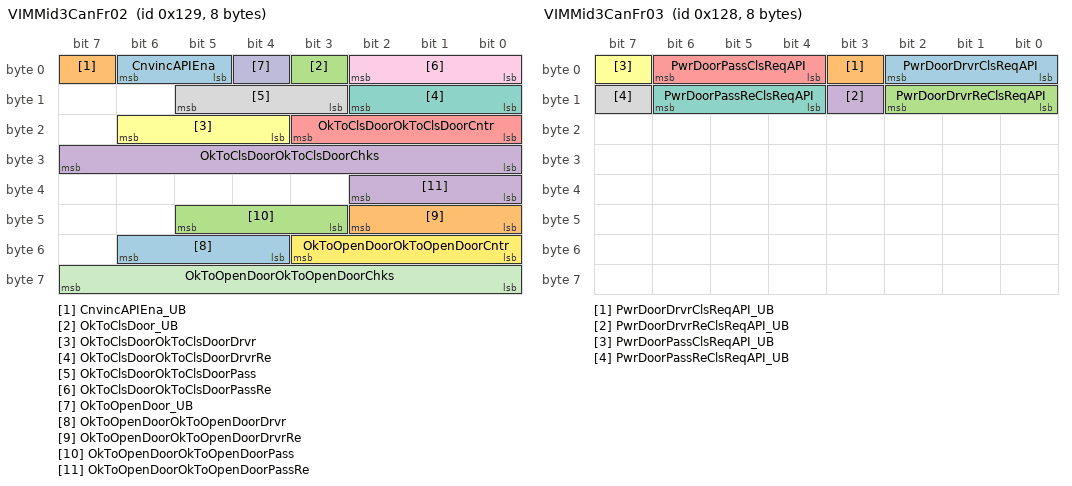
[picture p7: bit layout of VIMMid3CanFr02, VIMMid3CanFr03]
BO_ 297 VIMMid3CanFr02 : 8 VIM
 SG_ CnvincAPIEna : 6|2@0+ (1,0) [0|3] "" VCU1
 SG_ CnvincAPIEna_UB : 7|1@0+ (1,0) [0|1] "" VCU1
 SG_ OkToClsDoor_UB : 3|1@0+ (1,0) [0|1] "" VCU1
 SG_ OkToClsDoorOkToClsDoorChks : 31|8@0+ (1.0,0.0) [0.0|255.0] "Unitless" VCU1
 SG_ OkToClsDoorOkToClsDoorCntr : 19|4@0+ (1.0,0.0) [0.0|15.0] "Unitless" VCU1
 SG_ OkToClsDoorOkToClsDoorDrvr : 22|3@0+ (1,0) [0|7] "" VCU1
 SG_ OkToClsDoorOkToClsDoorDrvrRe : 10|3@0+ (1,0) [0|7] "" VCU1
 SG_ OkToClsDoorOkToClsDoorPass : 13|3@0+ (1,0) [0|7] "" VCU1
 SG_ OkToClsDoorOkToClsDoorPassRe : 2|3@0+ (1,0) [0|7] "" VCU1
 SG_ OkToOpenDoor_UB : 4|1@0+ (1,0) [0|1] "" VCU1
 SG_ OkToOpenDoorOkToOpenDoorChks : 63|8@0+ (1.0,0.0) [0.0|255.0] "Unitless" VCU1
 SG_ OkToOpenDoorOkToOpenDoorCntr : 51|4@0+ (1.0,0.0) [0.0|15.0] "Unitless" VCU1
 SG_ OkToOpenDoorOkToOpenDoorDrvr : 54|3@0+ (1,0) [0|7] "" VCU1
 SG_ OkToOpenDoorOkToOpenDoorDrvrRe : 42|3@0+ (1,0) [0|7] "" VCU1
 SG_ OkToOpenDoorOkToOpenDoorPass : 45|3@0+ (1,0) [0|7] "" VCU1
 SG_ OkToOpenDoorOkToOpenDoorPassRe : 34|3@0+ (1,0) [0|7] "" VCU1

BO_ 296 VIMMid3CanFr03 : 8 VIM
 SG_ PwrDoorDrvrClsReqAPI : 2|3@0+ (1,0) [0|7] "" VCU1
 SG_ PwrDoorDrvrClsReqAPI_UB : 3|1@0+ (1,0) [0|1] "" VCU1
 SG_ PwrDoorDrvrReClsReqAPI : 10|3@0+ (1,0) [0|7] "" VCU1
 SG_ PwrDoorDrvrReClsReqAPI_UB : 11|1@0+ (1,0) [0|1] "" VCU1
 SG_ PwrDoorPassClsReqAPI : 6|3@0+ (1,0) [0|7] "" VCU1
 SG_ PwrDoorPassClsReqAPI_UB : 7|1@0+ (1,0) [0|1] "" VCU1
 SG_ PwrDoorPassReClsReqAPI : 14|3@0+ (1,0) [0|7] "" VCU1
 SG_ PwrDoorPassReClsReqAPI_UB : 15|1@0+ (1,0) [0|1] "" VCU1

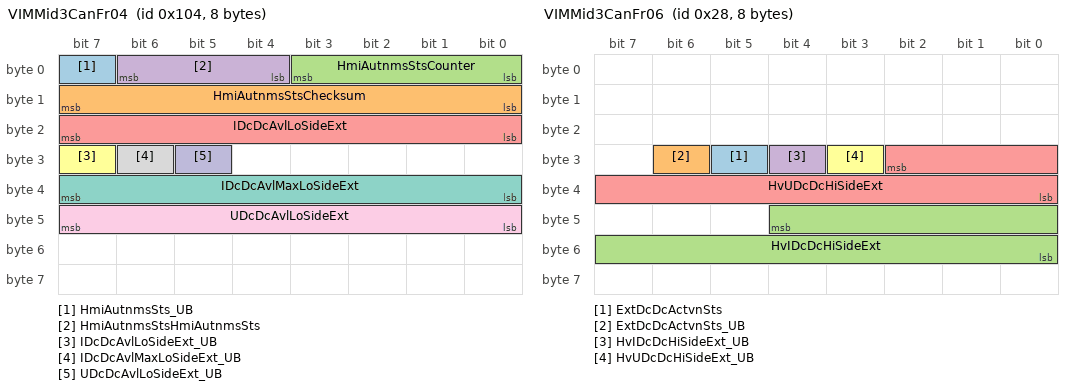
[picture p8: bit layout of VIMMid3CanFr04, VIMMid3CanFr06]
BO_ 260 VIMMid3CanFr04 : 8 VIM
 SG_ HmiAutnmsSts_UB : 7|1@0+ (1,0) [0|1] "" VCU1
 SG_ HmiAutnmsStsChecksum : 15|8@0+ (1.0,0.0) [0.0|255.0] "Unitless" VCU1
 SG_ HmiAutnmsStsCounter : 3|4@0+ (1.0,0.0) [0.0|15.0] "Unitless" VCU1
 SG_ HmiAutnmsStsHmiAutnmsSts : 6|3@0+ (1,0) [0|7] "" VCU1
 SG_ IDcDcAvlLoSideExt : 23|8@0+ (1.0,0.0) [0.0|254.0] "A" VCU1
 SG_ IDcDcAvlLoSideExt_UB : 31|1@0+ (1,0) [0|1] "" VCU1
 SG_ IDcDcAvlMaxLoSideExt : 39|8@0+ (1.0,0.0) [0.0|254.0] "A" VCU1
 SG_ IDcDcAvlMaxLoSideExt_UB : 30|1@0+ (1,0) [0|1] "" VCU1
 SG_ UDcDcAvlLoSideExt : 47|8@0+ (0.1,0.0) [0.0|25.0] "Volt" VCU1
 SG_ UDcDcAvlLoSideExt_UB : 29|1@0+ (1,0) [0|1] "" VCU1

BO_ 35 VIMMid3CanFr05 : 8 VIM
 SG_ ExtDcDcActvnSts2 : 6|1@0+ (1,0) [0|1] "" VCU1
 SG_ ExtDcDcActvnSts2_UB : 7|1@0+ (1,0) [0|1] "" VCU1

BO_ 40 VIMMid3CanFr06 : 8 VIM
 SG_ ExtDcDcActvnSts : 29|1@0+ (1,0) [0|1] "" VCU1
 SG_ ExtDcDcActvnSts_UB : 30|1@0+ (1,0) [0|1] "" VCU1
 SG_ HvIDcDcHiSideExt : 44|13@0+ (0.1,-410.0) [-410.0|409.1] "A" VCU1
 SG_ HvIDcDcHiSideExt_UB : 28|1@0+ (1,0) [0|1] "" VCU1
 SG_ HvUDcDcHiSideExt : 26|11@0+ (0.25,0.0) [0.0|511.0] "Volt" VCU1
 SG_ HvUDcDcHiSideExt_UB : 27|1@0+ (1,0) [0|1] "" VCU1

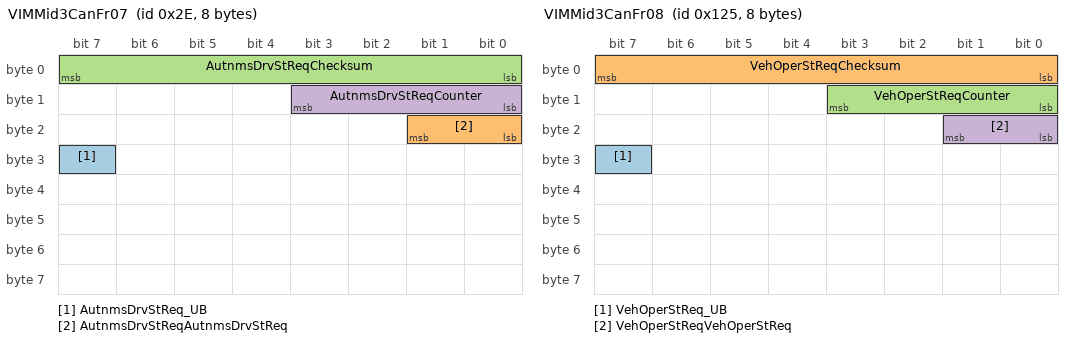
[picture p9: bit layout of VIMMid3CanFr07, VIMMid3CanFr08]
BO_ 46 VIMMid3CanFr07 : 8 VIM
 SG_ AutnmsDrvStReq_UB : 31|1@0+ (1,0) [0|1] "" VCU1
 SG_ AutnmsDrvStReqAutnmsDrvStReq : 16|2@1+ (1,0) [0|3] "" VCU1
 SG_ AutnmsDrvStReqChecksum : 0|8@1+ (1.0,0.0) [0.0|255.0] "Unitless" VCU1
 SG_ AutnmsDrvStReqCounter : 8|4@1+ (1.0,0.0) [0.0|15.0] "Unitless" VCU1

BO_ 293 VIMMid3CanFr08 : 8 VIM
 SG_ VehOperStReq_UB : 31|1@0+ (1,0) [0|1] "" VCU1
 SG_ VehOperStReqChecksum : 0|8@1+ (1.0,0.0) [0.0|255.0] "Unitless" VCU1
 SG_ VehOperStReqCounter : 8|4@1+ (1.0,0.0) [0.0|15.0] "Unitless" VCU1
 SG_ VehOperStReqVehOperStReq : 16|2@1+ (1,0) [0|3] "" VCU1

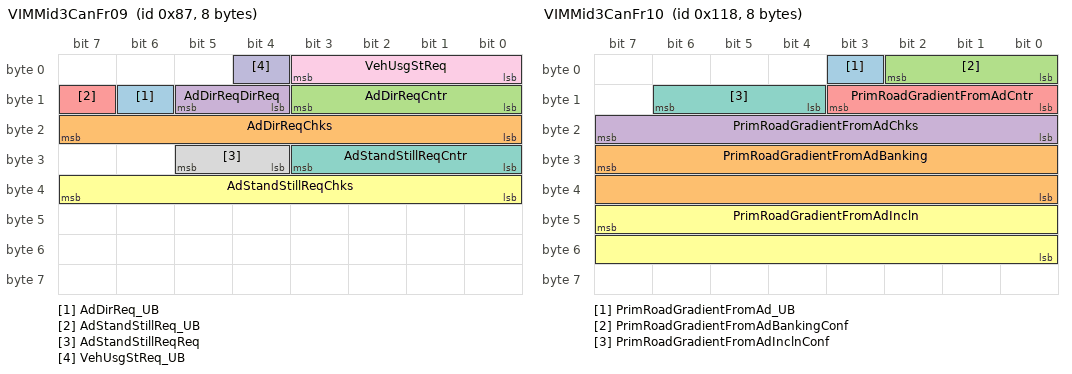
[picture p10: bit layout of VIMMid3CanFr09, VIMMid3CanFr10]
BO_ 135 VIMMid3CanFr09 : 8 VIM
 SG_ AdDirReq_UB : 14|1@0+ (1,0) [0|1] "" SSM,VCU1
 SG_ AdDirReqChks : 23|8@0+ (1.0,0.0) [0.0|255.0] "Unitless" SSM,VCU1
 SG_ AdDirReqCntr : 11|4@0+ (1.0,0.0) [0.0|15.0] "Unitless" SSM,VCU1
 SG_ AdDirReqDirReq : 13|2@0+ (1,0) [0|3] "" SSM,VCU1
 SG_ AdStandStillReq_UB : 15|1@0+ (1,0) [0|1] "" VCU1
 SG_ AdStandStillReqChks : 39|8@0+ (1.0,0.0) [0.0|255.0] "Unitless" VCU1
 SG_ AdStandStillReqCntr : 27|4@0+ (1.0,0.0) [0.0|15.0] "Unitless" VCU1
 SG_ AdStandStillReqReq : 29|2@0+ (1,0) [0|3] "" VCU1
 SG_ VehUsgStReq : 3|4@0+ (1,0) [0|15] "" VCU1
 SG_ VehUsgStReq_UB : 4|1@0+ (1,0) [0|1] "" VCU1

BO_ 280 VIMMid3CanFr10 : 8 VIM
 SG_ PrimRoadGradientFromAd_UB : 3|1@0+ (1,0) [0|1] "" SSM,VCU1
 SG_ PrimRoadGradientFromAdBanking : 31|16@0- (0.000030518,0.0) [-0.9999833060000001|0.9999833060000001] "rad" SSM,VCU1
 SG_ PrimRoadGradientFromAdBankingConf : 2|3@0+ (1,0) [0|7] "" SSM,VCU1
 SG_ PrimRoadGradientFromAdChks : 23|8@0+ (1.0,0.0) [0.0|255.0] "Unitless" SSM,VCU1
 SG_ PrimRoadGradientFromAdCntr : 11|4@0+ (1.0,0.0) [0.0|15.0] "Unitless" SSM,VCU1
 SG_ PrimRoadGradientFromAdIncln : 47|16@0- (0.000030518,0.0) [-0.9999833060000001|0.9999833060000001] "rad" SSM,VCU1
 SG_ PrimRoadGradientFromAdInclnConf : 14|3@0+ (1,0) [0|7] "" SSM,VCU1

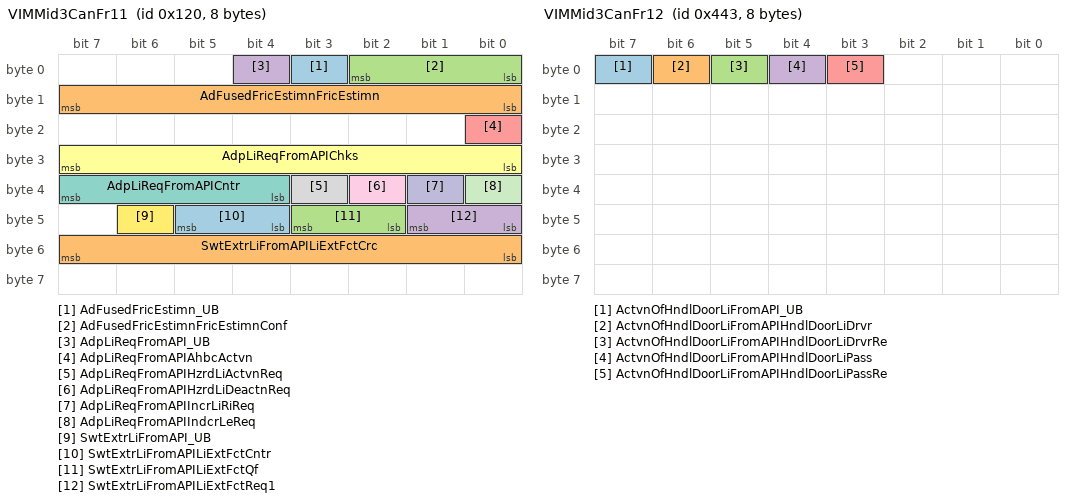
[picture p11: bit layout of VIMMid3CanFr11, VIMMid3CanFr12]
BO_ 288 VIMMid3CanFr11 : 8 VIM
 SG_ AdFusedFricEstimn_UB : 3|1@0+ (1,0) [0|1] "" VCU1
 SG_ AdFusedFricEstimnFricEstimn : 15|8@0+ (0.01,0.0) [0.0|2.0] "Unitless" VCU1
 SG_ AdFusedFricEstimnFricEstimnConf : 2|3@0+ (1,0) [0|7] "" VCU1
 SG_ AdpLiReqFromAPI_UB : 4|1@0+ (1,0) [0|1] "" VCU1
 SG_ AdpLiReqFromAPIAhbcActvn : 16|1@0+ (1,0) [0|1] "" VCU1
 SG_ AdpLiReqFromAPIChks : 31|8@0+ (1.0,0.0) [0.0|255.0] "Unitless" VCU1
 SG_ AdpLiReqFromAPICntr : 39|4@0+ (1.0,0.0) [0.0|15.0] "Unitless" VCU1
 SG_ AdpLiReqFromAPIHzrdLiActvnReq : 35|1@0+ (1,0) [0|1] "" VCU1
 SG_ AdpLiReqFromAPIHzrdLiDeactnReq : 34|1@0+ (1,0) [0|1] "" VCU1
 SG_ AdpLiReqFromAPIIncrLiRiReq : 33|1@0+ (1,0) [0|1] "" VCU1
 SG_ AdpLiReqFromAPIIndcrLeReq : 32|1@0+ (1,0) [0|1] "" VCU1
 SG_ SwtExtrLiFromAPI_UB : 46|1@0+ (1,0) [0|1] "" VCU1
 SG_ SwtExtrLiFromAPILiExtFctCntr : 45|2@0+ (1.0,0.0) [0.0|3.0] "Unitless" VCU1
 SG_ SwtExtrLiFromAPILiExtFctCrc : 55|8@0+ (1.0,0.0) [0.0|255.0] "Unitless" VCU1
 SG_ SwtExtrLiFromAPILiExtFctQf : 43|2@0+ (1,0) [0|3] "" VCU1
 SG_ SwtExtrLiFromAPILiExtFctReq1 : 41|2@0+ (1,0) [0|3] "" VCU1

BO_ 1091 VIMMid3CanFr12 : 8 VIM
 SG_ ActvnOfHndlDoorLiFromAPI_UB : 7|1@0+ (1,0) [0|1] "" VCU1
 SG_ ActvnOfHndlDoorLiFromAPIHndlDoorLiDrvr : 6|1@0+ (1,0) [0|1] "" VCU1
 SG_ ActvnOfHndlDoorLiFromAPIHndlDoorLiDrvrRe : 5|1@0+ (1,0) [0|1] "" VCU1
 SG_ ActvnOfHndlDoorLiFromAPIHndlDoorLiPass : 4|1@0+ (1,0) [0|1] "" VCU1
 SG_ ActvnOfHndlDoorLiFromAPIHndlDoorLiPassRe : 3|1@0+ (1,0) [0|1] "" VCU1

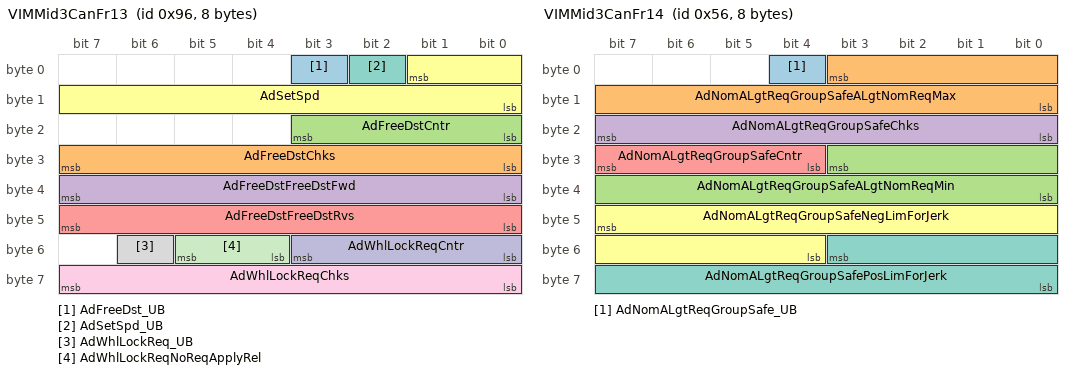
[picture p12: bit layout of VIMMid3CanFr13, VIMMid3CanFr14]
BO_ 150 VIMMid3CanFr13 : 8 VIM
 SG_ AdFreeDst_UB : 3|1@0+ (1,0) [0|1] "" VCU1
 SG_ AdFreeDstChks : 31|8@0+ (1.0,0.0) [0.0|255.0] "Unitless" VCU1
 SG_ AdFreeDstCntr : 19|4@0+ (1.0,0.0) [0.0|15.0] "Unitless" VCU1
 SG_ AdFreeDstFreeDstFwd : 39|8@0+ (0.02,0.0) [0.0|5.0] "m" VCU1
 SG_ AdFreeDstFreeDstRvs : 47|8@0+ (0.02,0.0) [0.0|5.0] "m" VCU1
 SG_ AdSetSpd : 1|10@0+ (0.1,0.0) [0.0|60.0] "m/s" VCU1
 SG_ AdSetSpd_UB : 2|1@0+ (1,0) [0|1] "" VCU1
 SG_ AdWhlLockReq_UB : 54|1@0+ (1,0) [0|1] "" SSM,VCU1
 SG_ AdWhlLockReqChks : 63|8@0+ (1.0,0.0) [0.0|255.0] "Unitless" SSM,VCU1
 SG_ AdWhlLockReqCntr : 51|4@0+ (1.0,0.0) [0.0|15.0] "Unitless" SSM,VCU1
 SG_ AdWhlLockReqNoReqApplyRel : 53|2@0+ (1,0) [0|3] "" SSM,VCU1

BO_ 86 VIMMid3CanFr14 : 8 VIM
 SG_ AdNomALgtReqGroupSafe_UB : 4|1@0+ (1,0) [0|1] "" SSM,VCU1
 SG_ AdNomALgtReqGroupSafeALgtNomReqMax : 3|12@0+ (0.0078125,-15.0) [-15.0|15.0] "m/s^2" SSM,VCU1
 SG_ AdNomALgtReqGroupSafeALgtNomReqMin : 27|12@0+ (0.0078125,-15.0) [-15.0|15.0] "m/s^2" SSM,VCU1
 SG_ AdNomALgtReqGroupSafeChks : 23|8@0+ (1.0,0.0) [0.0|255.0] "Unitless" SSM,VCU1
 SG_ AdNomALgtReqGroupSafeCntr : 31|4@0+ (1.0,0.0) [0.0|15.0] "Unitless" SSM,VCU1
 SG_ AdNomALgtReqGroupSafeNegLimForJerk : 47|12@0+ (0.05,-100.0) [-100.0|100.0] "m/s^3" SSM,VCU1
 SG_ AdNomALgtReqGroupSafePosLimForJerk : 51|12@0+ (0.05,-100.0) [-100.0|100.0] "m/s^3" SSM,VCU1

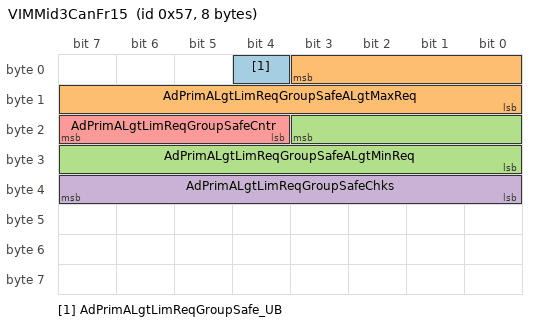
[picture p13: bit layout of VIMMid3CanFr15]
BO_ 87 VIMMid3CanFr15 : 8 VIM
 SG_ AdPrimALgtLimReqGroupSafe_UB : 4|1@0+ (1,0) [0|1] "" SSM,VCU1
 SG_ AdPrimALgtLimReqGroupSafeALgtMaxReq : 3|12@0+ (0.0078125,-15.0) [-15.0|15.0] "m/s^2" SSM,VCU1
 SG_ AdPrimALgtLimReqGroupSafeALgtMinReq : 19|12@0+ (0.0078125,-15.0) [-15.0|15.0] "m/s^2" SSM,VCU1
 SG_ AdPrimALgtLimReqGroupSafeChks : 39|8@0+ (1.0,0.0) [0.0|255.0] "Unitless" SSM,VCU1
 SG_ AdPrimALgtLimReqGroupSafeCntr : 23|4@0+ (1.0,0.0) [0.0|15.0] "Unitless" SSM,VCU1

BO_ 1288 VimMid3CanNmFr : 8 VIM
 SG_ Body_VIM : 21|1@0+ (1,0) [0|0] "" VCU1
 SG_ Brake_VIM : 33|1@0+ (1,0) [0|0] "" VCU1
 SG_ Diesel_VIM : 32|1@0+ (1,0) [0|0] "" VCU1
 SG_ Hazard_VIM : 18|1@0+ (1,0) [0|0] "" VCU1
 SG_ InfotainmentAndHMI_VIM : 22|1@0+ (1,0) [0|0] "" VCU1
 SG_ PNCCharging_VIM : 25|1@0+ (1,0) [0|0] "" VCU1
 SG_ PNCDriverinfo_VIM : 16|1@0+ (1,0) [0|0] "" VCU1
 SG_ PNCDriverinfoPoll_VIM : 31|1@0+ (1,0) [0|0] "" VCU1
 SG_ PNCDriving_VIM : 27|1@0+ (1,0) [0|0] "" VCU1
 SG_ PNCEntrance_VIM : 23|1@0+ (1,0) [0|0] "" VCU1
 SG_ PNCGlobal_VIM : 29|1@0+ (1,0) [0|0] "" VCU1
 SG_ PNCGSD_VIM : 30|1@0+ (1,0) [0|0] "" VCU1
 SG_ PNCHVEnergyStorage_VIM : 35|1@0+ (1,0) [0|0] "" VCU1
 SG_ PNCLocking_VIM : 17|1@0+ (1,0) [0|0] "" VCU1
 SG_ PNCPreClimatization_VIM : 26|1@0+ (1,0) [0|0] "" VCU1
 SG_ PNCSpare1_VIM : 39|1@0+ (1,0) [0|0] "" VCU1
 SG_ PNCSpare2_VIM : 38|1@0+ (1,0) [0|0] "" VCU1
 SG_ PNCSpare3_VIM : 37|1@0+ (1,0) [0|0] "" VCU1
 SG_ PNCSpare4_VIM : 36|1@0+ (1,0) [0|0] "" VCU1
 SG_ PNCStart_VIM : 24|1@0+ (1,0) [0|0] "" VCU1
 SG_ PNCTrailerCaravan_VIM : 28|1@0+ (1,0) [0|0] "" VCU1
 SG_ VehicleAPI_VIM : 34|1@0+ (1,0) [0|0] "" VCU1
 SG_ Visibility_VIM : 20|1@0+ (1,0) [0|0] "" VCU1
 SG_ WarningSounds_VIM : 19|1@0+ (1,0) [0|0] "" VCU1
 SG_ NM_PNI_VIM : 14|1@0+ (1,0) [0|0] "" VCU1
 SG_ NM_AW_VIM : 12|1@0+ (1,0) [0|0] "" VCU1
 SG_ NM_CS_VIM : 11|1@0+ (1,0) [0|0] "" VCU1
 SG_ NM_RMR_VIM : 8|1@0+ (1,0) [0|0] "" VCU1
 SG_ NM_NodeID_VIM : 7|8@0+ (1,0) [0|0] "" VCU1

CM_ SG_ 1120 CllsnAidSnvtySeldPen "'Distribution of the setting Collision Avoidance Sensitivity Level  
' The profile id associated with the setting value";
CM_ SG_ 1120 CllsnAidSnvtySeldSts "'Distribution of the setting Collision Avoidance Sensitivity Level  
' The setting value";
CM_ SG_ 1120 CllsnFwdWarnReq "Request to activate collision warning against forward object";
CM_ SG_ 1120 CllsnThreat "The current collision threat level.";
CM_ SG_ 1120 CnclReqForCrsCtrl "Request from Active safety actuation manager to immediately cancel ACC or Cruise Control and inhibit activation.";
CM_ SG_ 1120 CooltFlowInDtElecForExt "PredictedCoolant flow for Electric Drivetrain (ED) coolant circuit.";
CM_ SG_ 1120 CooltTInDtElecForExt "Coolant temperature for the Electric Drivetrain (ED) cooling circuit.";
CM_ SG_ 1120 IndcrDisp1WdSts "Controls the Direction Indicator tell-tales and sound to the driver.

Signal will be event driven and holds every flank on and off of the telltales/sound.

This signal will not be used for the Hazard Warning Light Button in instrument panel.";
CM_ SG_ 1120 IndcrTurnSts1WdSts "Provides the state and not the event of HWL/Direction Indicator.";
CM_ SG_ 1120 SrvRqrdForCllsnAid "'Service Required' message for all Collision Avoidance functions";
CM_ SG_ 1084 BeamHiIndcnDisp "High Beam Indication.

Controls the High Beam indication (blue tell-tale) to the driver (On/Off).";
CM_ SG_ 1084 BltLockStAtRowSecMidForBltLockEquid "State of belt lock at seating position at middle of second row If the belt lock is equipped";
CM_ SG_ 1084 BltLockStAtRowSecMidForBltLockSt1 "State of belt lock at seating position at middle of second row Belt lock state,  locked/unlocked";
CM_ SG_ 1084 BltLockStAtRowSecMidForBltLockSts "State of belt lock at seating position at middle of second row Belt lock status, OK/NOK";
CM_ SG_ 1084 FltIndcrTurnLeFrnt "Light source failure (open load or short circuit) indication to driver, left front direction indicator.";
CM_ SG_ 1084 FltIndcrTurnLeRe "Light source failure (open load or short circuit) indication to driver, left rear direction indicator.";
CM_ SG_ 1084 FltIndcrTurnRiFrnt "Light source failure (open load or short circuit) indication to driver, right front direction indicator.";
CM_ SG_ 1084 FltIndcrTurnRiRe "Light source failure (open load or short circuit) indication to driver, right rear direction indicator.";
CM_ SG_ 1084 FltLiRvsg "Light source failure (open load or short circuit) indication to driver, reversing light.";
CM_ SG_ 1084 FltOfBeamHiLe "Light source failure (open load or short circuit) indication to driver, left high beam.";
CM_ SG_ 1084 FltOfBeamHiRi "Light source failure (open load or short circuit) indication to driver, right high beam.";
CM_ SG_ 1084 FltOfBeamLoLe "Light source failure (open load or short circuit) indication to driver, left low beam.";
CM_ SG_ 1084 FltOfBeamLoRi "Light source failure (open load or short circuit) indication to driver, right low beam.";
CM_ SG_ 1084 FltOfBrkLiHiMntd "Light source failure (open load or short circuit) indication to driver, CHMSL.";
CM_ SG_ 1084 FltOfBrkLiLe "Light source failure (open load or short circuit) indication to driver, brake light left.";
CM_ SG_ 1084 FltOfBrkLiRi "Light source failure (open load or short circuit) indication to driver, brake light right.";
CM_ SG_ 1084 FltOfFogLiFrnt "Light source failure (open load or short circuit) indication to driver, fog light front.";
CM_ SG_ 1084 FltOfLiPosnFrntLe "Light source failure (open load or short circuit) indication to driver, left front position light.";
CM_ SG_ 1084 FltOfLiPosnFrntRi "Light source failure (open load or short circuit) indication to driver, right front position light.";
CM_ SG_ 1084 FltOfPlateNr "Light source failure (open load or short circuit) indication to driver, reg plate light.";
CM_ SG_ 1084 FltOfPosnReLe "Light source failure (open load or short circuit) indication to driver, left rear position light.";
CM_ SG_ 1084 FltOfPosnReRi "Light source failure (open load or short circuit) indication to driver, right rear position light.";
CM_ SG_ 1084 HdlampSysFailr "Indication of fault in subsystem for swiveling, leveling or low beam LED.";
CM_ SG_ 1084 SysBrkLiFailr "Indication of Brake Light system failure to the driver.

Values:
No Fault or Fault.";
CM_ SG_ 1084 SysDirIndcnFailr "Indication of Direction Indicator system failure to the driver.

Values:
No Fault or Fault.";
CM_ SG_ 512 AsySftyDecelEnadByVehDyn "Signal indicating that autonomous braking in safety critical situation is allowed by vehicle dynamics.";
CM_ SG_ 512 EngOilPWarn "Request to set low engine oil pressure warning to driver";
CM_ SG_ 512 InhbOfAsySftyDecelByVehDyn "Signal that aborts an ongoing CMbB intervention and prevents any new interventions this driving cycle.";
CM_ SG_ 512 PrpsnErrIndcnReq "MIL signal sent to DIM";
CM_ SG_ 512 RoadLoadNomCoeff0 "Polynom coefficients for road load estimation f0Nom";
CM_ SG_ 512 RoadLoadNomCoeff1 "Polynom coefficients for road load estimation f1Nom";
CM_ SG_ 512 RoadLoadNomCoeff2 "Polynom coefficients for road load estimation f2Nom";
CM_ SG_ 512 RoadLoadNomCoeffSts "Polynom coefficients for road load estimation Calculated road load avaliable";
CM_ SG_ 512 TankFlapSts "TankFlapSts -Tank Flap Status

Ukwn - Unknown status
Opend - Opened
Clsd - Closed";
CM_ SG_ 512 TrsmFltIndcn "TCM uses signal Transmission Fault Indication to request text message ilumination to driver. Signal is transmitted to both ECM and DIM.

Signal consits of 32 slots. One slot = one unique text message.

Default value = 0 (No request)

";
CM_ SG_ 384 ALnchTiDly3Qf "Acceleration Launch Time Delay from Standstill position Quality Factor";
CM_ SG_ 384 ALnchTiDly3Sec2 "Acceleration Launch Time Delay from Standstill position Time Delay";
CM_ SG_ 384 AlrmSt "Indicates alarm status, last trigger source and alarm component errors.";
CM_ SG_ 384 AlrmTrgSrc "Indicates alarm status, last trigger source and alarm component errors.";
CM_ SG_ 384 DoorDrvrReSts "DoorDrvrReSts - Driver Side Rear Door Status

Ukwn - Unknown status
Opend - Opened
Clsd - Closed";
CM_ SG_ 384 DoorDrvrSts "DoorDrvrSts - Driver Door Status

Ukwn - Unknown status
Opend - Opened
Clsd - Closed";
CM_ SG_ 384 DoorPassReSts "DoorPassReSts - Passenger Side Rear Door Status

Ukwn - Unknown status
Opend - Opened
Clsd - Closed";
CM_ SG_ 384 DoorPassSts "DoorPassSts - Passenger Door Status

Ukwn - Unknown status
Opend - Opened
Clsd - Closed";
CM_ SG_ 384 EngOilLvlSts "Engine oil level status information.
If no status currently can be derived 'Not available' will be shown.";
CM_ SG_ 384 HoodSts "HoodSts - Hood Status

Ukwn - Unknown status
Opend - Opened
Clsd - Closed";
CM_ SG_ 384 SnsrInclnFailr "Indicates alarm status, last trigger source and alarm component errors.";
CM_ SG_ 384 SnsrIntrScanrFailr "Indicates alarm status, last trigger source and alarm component errors.";
CM_ SG_ 384 SnsrSoundrBattBackedFailr "Indicates alarm status, last trigger source and alarm component errors.";
CM_ SG_ 384 TrSts "TrSts - Tailgate/Bootlid Status

Ukwn - Unknown status
Opend - Opened
Clsd - Closed";
CM_ SG_ 119 AccrPedlPsdAccrPedlPsd "Describes if the accelerator pedal is pressed. Will indicate pressed for a small pedal press.
Accompanying status signal will indicate the integrity of the information.";
CM_ SG_ 119 AccrPedlPsdAccrPedlPsdChks "Describes if the accelerator pedal is pressed. Will indicate pressed for a small pedal press.
Accompanying status signal will indicate the integrity of the information.";
CM_ SG_ 119 AccrPedlPsdAccrPedlPsdCntr "Describes if the accelerator pedal is pressed. Will indicate pressed for a small pedal press.
Accompanying status signal will indicate the integrity of the information.";
CM_ SG_ 119 AccrPedlPsdAccrPedlPsdSts "Describes if the accelerator pedal is pressed. Will indicate pressed for a small pedal press.
Accompanying status signal will indicate the integrity of the information. AccrPedlPsd fulfills ASIL C integrity";
CM_ SG_ 119 AsySftyBrkDlyEstimd "Estimated time to achieve 5 m/s^2 deceleration if an intervention request was received.";
CM_ SG_ 119 BrkPedlNotPsdSafe "BrkPedlPsd gives the information that the driver presses the brake pedal or not with ASIL B integrity. 
0= No, brake pedal is not pressed
1=Yes, brake pedal is pressed

QF for BrkPedlPsd is defined according to below:
0 = Invalid BrkPedlPsd information
1 = Initialization
2 = Providing BrkPedlPsd information with QM integrity
3 = Providing BrkPedlPsd  information with ASIL B integrity

BrkPedlNotPsdSafe information that driver does not press the brake pedal with ASIL C integrity.
0= No, to be considered as undefined state and not be considered as 'brake pedal pressed'.
1= Yes, brake pedal is considered to be not pressed with an integrity of ASIL C. Brake pedal not pressed with ASIL C integrity";
CM_ SG_ 119 BrkPedlPsd "BrkPedlPsd gives the information that the driver presses the brake pedal or not with ASIL B integrity. 
0= No, brake pedal is not pressed
1=Yes, brake pedal is pressed

QF for BrkPedlPsd is defined according to below:
0 = Invalid BrkPedlPsd information
1 = Initialization
2 = Providing BrkPedlPsd information with QM integrity
3 = Providing BrkPedlPsd  information with ASIL B integrity

BrkPedlNotPsdSafe information that driver does not press the brake pedal with ASIL C integrity.
0= No, to be considered as undefined state and not be considered as 'brake pedal pressed'.
1= Yes, brake pedal is considered to be not pressed with an integrity of ASIL C. Brake pedal pressed with ASIL B integrity";
CM_ SG_ 119 BrkPedlPsdChks "BrkPedlPsd gives the information that the driver presses the brake pedal or not with ASIL B integrity. 
0= No, brake pedal is not pressed
1=Yes, brake pedal is pressed

QF for BrkPedlPsd is defined according to below:
0 = Invalid BrkPedlPsd information
1 = Initialization
2 = Providing BrkPedlPsd information with QM integrity
3 = Providing BrkPedlPsd  information with ASIL B integrity

BrkPedlNotPsdSafe information that driver does not press the brake pedal with ASIL C integrity.
0= No, to be considered as undefined state and not be considered as 'brake pedal pressed'.
1= Yes, brake pedal is considered to be not pressed with an integrity of ASIL C. Checksum for brake pedal pressed information";
CM_ SG_ 119 BrkPedlPsdCntr "BrkPedlPsd gives the information that the driver presses the brake pedal or not with ASIL B integrity. 
0= No, brake pedal is not pressed
1=Yes, brake pedal is pressed

QF for BrkPedlPsd is defined according to below:
0 = Invalid BrkPedlPsd information
1 = Initialization
2 = Providing BrkPedlPsd information with QM integrity
3 = Providing BrkPedlPsd  information with ASIL B integrity

BrkPedlNotPsdSafe information that driver does not press the brake pedal with ASIL C integrity.
0= No, to be considered as undefined state and not be considered as 'brake pedal pressed'.
1= Yes, brake pedal is considered to be not pressed with an integrity of ASIL C. Counter value for brake pedal pressed information";
CM_ SG_ 119 BrkPedlPsdQf "BrkPedlPsd gives the information that the driver presses the brake pedal or not with ASIL B integrity. 
0= No, brake pedal is not pressed
1=Yes, brake pedal is pressed

QF for BrkPedlPsd is defined according to below:
0 = Invalid BrkPedlPsd information
1 = Initialization
2 = Providing BrkPedlPsd information with QM integrity
3 = Providing BrkPedlPsd  information with ASIL B integrity

BrkPedlNotPsdSafe information that driver does not press the brake pedal with ASIL C integrity.
0= No, to be considered as undefined state and not be considered as 'brake pedal pressed'.
1= Yes, brake pedal is considered to be not pressed with an integrity of ASIL C. Qf for brake pedal pressed ASIL B signal";
CM_ SG_ 119 OvrdDecelByDrvrOvrdDecelByDrvr "Reports the driver intent to override a deceleration. Based on Accelerator pedal being distinctively pressed.";
CM_ SG_ 119 OvrdDecelByDrvrOvrdDecelByDrvrChks "Reports the driver intent to override a deceleration. Based on Accelerator pedal being distinctively pressed.";
CM_ SG_ 119 OvrdDecelByDrvrOvrdDecelByDrvrCntr "Reports the driver intent to override a deceleration. Based on Accelerator pedal being distinctively pressed.";
CM_ SG_ 104 AccrPedlRat "Accelerator Pedal Position with adapted 0 point. Value as percentage of fully pressed pedal.";
CM_ SG_ 104 ChrgnUReqExt "Setpoint votlage for LV side of External DCDC";
CM_ SG_ 104 DrvrDecelReq "Driver deceleration request. The signal is generated based on driver requested brake torque (brake pedal applied torque only), vehicle load estimation and road inclination calculations.";
CM_ SG_ 104 PtGearAct "Actual gear.";
CM_ SG_ 104 TirePWarnFrntRiTirePWarn " Warning level";
CM_ SG_ 104 TirePWarnFrntRiTirePWarnType " Specification of which system raised warning";
CM_ SG_ 104 TirePWarnReLeTirePWarn " Warning level";
CM_ SG_ 104 TirePWarnReLeTirePWarnType " Specification of which system raised warning";
CM_ SG_ 104 TirePWarnReRiTirePWarn " Warning level";
CM_ SG_ 104 TirePWarnReRiTirePWarnType " Specification of which system raised warning";
CM_ SG_ 88 PtTqAtAxleFrntAct "Actual torque delivered by the powertrain to the front axle (torque before propshaft to rear subtracts torque from front).  Actual torque on front axle. Not compensated for inertia, exception open converter.";
CM_ SG_ 88 PtTqAtWhlFrntLeAct "Actual torque delivered by the powertrain to the front axle (torque before propshaft to rear subtracts torque from front).  Actual torque on front left wheel. Compensated for inertia.";
CM_ SG_ 88 PtTqAtWhlFrntRiAct "Actual torque delivered by the powertrain to the front axle (torque before propshaft to rear subtracts torque from front).  Actual torque on front right wheel. Compensated for inertia.";
CM_ SG_ 88 PtTqAtWhlsFrntQly "Actual torque delivered by the powertrain to the front axle (torque before propshaft to rear subtracts torque from front).  Quality for estimated front axle and wheel torque";
CM_ SG_ 89 PtTqAtAxleReAct "Actual rear axle torque provided by the powertrain.  Actual torque on rear axle. Not compensated for inertia.";
CM_ SG_ 89 PtTqAtWhlReLeAct "Actual rear axle torque provided by the powertrain.  Actual torque on rear left wheel. Compensated for inertia.";
CM_ SG_ 89 PtTqAtWhlReRiAct "Actual rear axle torque provided by the powertrain.  Actual torque on rear right wheel. Compensated for inertia.";
CM_ SG_ 89 PtTqAtWhlsReQly "Actual rear axle torque provided by the powertrain.  Quality for estimated rear axle and wheel torque";
CM_ SG_ 133 AdSecBrkActvnGroupSafeActvnReq "Request to activate and deactivate local AD-mode in Secondary Brake from VDM. Activation of local AD mode in secondary brake system from VDM to BC.";
CM_ SG_ 133 AdSecBrkActvnGroupSafeChks "Request to activate and deactivate local AD-mode in Secondary Brake from VDM. Checksum for E2E.";
CM_ SG_ 133 AdSecBrkActvnGroupSafeCntr "Request to activate and deactivate local AD-mode in Secondary Brake from VDM. Counter for E2E.";
CM_ SG_ 133 AdSecBrkActvnGroupSafeDeactvnReq "Request to activate and deactivate local AD-mode in Secondary Brake from VDM. Deactivation of local AD mode in secondary brake system, from VDM to BC.";
CM_ SG_ 133 BrkFricTqTotAtWhlsActBrkFricTqTotAtWhlsAct "Total actual friction brake toque at all four wheels. Total friction brake torque at all four wheels";
CM_ SG_ 133 BrkFricTqTotAtWhlsActBrkFricTqTotAtWhlsActChks "Total actual friction brake toque at all four wheels. Checksum";
CM_ SG_ 133 BrkFricTqTotAtWhlsActBrkFricTqTotAtWhlsActCntr "Total actual friction brake toque at all four wheels. Counter";
CM_ SG_ 133 PtTqAtAxleAvlFrntMaxLong "Maximum propulsive torque capability at front wheel axle long horizon.";
CM_ SG_ 352 TirePWarnCmnTirePWarn " Warning level";
CM_ SG_ 352 TirePWarnCmnTirePWarnType " Specification of which system raised warning";
CM_ SG_ 352 TirePWarnFrntLeTirePWarn " Warning level";
CM_ SG_ 352 TirePWarnFrntLeTirePWarnType " Specification of which system raised warning";
CM_ SG_ 120 PrimSteerMotTqSteerMotTq " Steering motor torque";
CM_ SG_ 120 PrimSteerMotTqSteerMotTqQf " Quality factor for SteerMotTq";
CM_ SG_ 391 DrvrIntvStsDrvrIntvByAccrPedl "Driver intervention  Driver intervention by accelerator pedal";
CM_ SG_ 391 DrvrIntvStsDrvrIntvByBrkPedl "Driver intervention  Driver intervention by brake pedal";
CM_ SG_ 391 DrvrIntvStsDrvrIntvBySteering "Driver intervention  Driver intervention by steering";
CM_ SG_ 391 DrvrPrsnt "Indicates whether a driver is present or not. Driver Present";
CM_ SG_ 391 DrvrPrsntQf "Indicates whether a driver is present or not. Driver Present quality factor";
CM_ SG_ 391 DrvrPrsntStsDrvrPrsntChks "Indicates whether a driver is present or not. Driver Present checksum";
CM_ SG_ 391 DrvrPrsntStsDrvrPrsntCntr "Indicates whether a driver is present or not. Driver Present counter";
CM_ SG_ 1136 AsySftyDecelReq "Active safety request signals for safety decceleration. Request for deceleration in safety critical situation.";
CM_ SG_ 1136 AsySftyEnaDecel "Active safety request signals for safety decceleration. Enable signal for deceleration in safety critical situation.";
CM_ SG_ 1136 SftyDecelGroupSafeChks "Active safety request signals for safety decceleration. Checksum";
CM_ SG_ 1136 SftyDecelGroupSafeCntr "Active safety request signals for safety decceleration. Counter";
CM_ SG_ 917 BattChrgnTiEstimdExt "Estimated charging time left.";
CM_ SG_ 917 BattIExt "Hv Battery current. Positive current is discharging the battery.";
CM_ SG_ 917 BattUExt "Hv Battery Voltage";
CM_ SG_ 917 ChrgnTypExt "Selected Charging type";
CM_ SG_ 917 ChrgrHndlStsExt "Status of the Onboard Charger connection to the grid. ";
CM_ SG_ 83 AutnmsDrvModMngtExtSafeAutnmsDrvModSts1 "Data element communicates if Autonomous Drive status is activated or not and if Vehicle Operator is present with E2E protection. If Autonomous Drive is activated or not.";
CM_ SG_ 83 AutnmsDrvModMngtExtSafeChecksum "Data element communicates if Autonomous Drive status is activated or not and if Vehicle Operator is present with E2E protection. Checksum used for E2E protection.";
CM_ SG_ 83 AutnmsDrvModMngtExtSafeCounter "Data element communicates if Autonomous Drive status is activated or not and if Vehicle Operator is present with E2E protection. Counter used for E2E protection.";
CM_ SG_ 83 AutnmsDrvModMngtExtSafeVehOperModSts1 "Data element communicates if Autonomous Drive status is activated or not and if Vehicle Operator is present with E2E protection. If VehicleOperatorMode is activated or not";
CM_ SG_ 83 BrkDegradedChks "Brake degraded status Checksum";
CM_ SG_ 83 BrkDegradedCntr "Brake degraded status Counter";
CM_ SG_ 83 BrkDegradedSts "Brake degraded status Brake degraded status";
CM_ SG_ 83 VehManDeactvnReqInProgs1 "If a user action is performed on the start/stop knob/button with the intention to decrease Usage Mode from Driving or Active, the information shall be sent to stakeholders.
0) NoReq, Start/stop device not actuated
1) BgnStopReq, Start/stop device actuated
2) StopReq, A user action that normally would turn off the vehicle has been detected
3) Resd, Reserved";
CM_ SG_ 83 VehUsgSt "External Vehicle usage mode request answer. Comparable to UsageModes";
CM_ SG_ 131 VehOpReqInVehDynGroupSafeChks " E2E-protection";
CM_ SG_ 131 VehOpReqInVehDynGroupSafeCntr " E2E-protection";
CM_ SG_ 131 VehOpReqInVehDynGroupSafeVehOpReq " Vehicle Operator request";
CM_ SG_ 1104 CornrStfnCornrStfnFrnt " Corner Stiffness Front";
CM_ SG_ 1104 CornrStfnCornrStfnQly " Corner Stiffness Quality";
CM_ SG_ 1104 CornrStfnCornrStfnRe " Corner Stiffness Rear";
CM_ SG_ 1104 HvBattLimnExt "Signal to inform about high voltage battery overheating event.";
CM_ SG_ 1104 LgtStfnLgtStfnFrnt " Longitudinal stiffness Front";
CM_ SG_ 1104 LgtStfnLgtStfnQly " Longitudinal stiffness Quality";
CM_ SG_ 1104 LgtStfnLgtStfnRe " Longitudinal stiffness Rear";
CM_ SG_ 311 TireRdEstimdAtWhlsFrLe " Front Left wheel radius";
CM_ SG_ 311 TireRdEstimdAtWhlsFrRi " Front Right Wheel Radius";
CM_ SG_ 311 TireRdEstimdAtWhlsReLe " Rear Left Wheel Radius";
CM_ SG_ 311 TireRdEstimdAtWhlsReRi " Rear Right Wheel radius";
CM_ SG_ 97 StandStillMgrStsForHldSafeChks " E2E Checksum";
CM_ SG_ 97 StandStillMgrStsForHldSafeCntr " E2E Counter";
CM_ SG_ 97 StandStillMgrStsForHldSafeStandStillSts " Vehicle hold status";
CM_ SG_ 97 SwtBeamHiToAPI "This signal reflects the status of the High Beam stalk.";
CM_ SG_ 97 SwtIndcrToAPIIndcrTypExtReq "This signal shows the position of the physical Turn Indicator stalk. Data";
CM_ SG_ 97 SwtIndcrToAPIIndcrTypExtReqChks "This signal shows the position of the physical Turn Indicator stalk. Checksum";
CM_ SG_ 97 SwtIndcrToAPIIndcrTypExtReqCntr "This signal shows the position of the physical Turn Indicator stalk. Counter";
CM_ SG_ 97 SwtIndcrToAPIIndcrTypExtReqToUpdQf "This signal shows the position of the physical Turn Indicator stalk. Qf";
CM_ SG_ 97 SwtLiHzrdWarnToAPI "This signal shows if the Hazar Warning Light button is pressed or not.";
CM_ SG_ 1092 AplidSwtExtrLiToAPILiExtFctCntr " Counter";
CM_ SG_ 1092 AplidSwtExtrLiToAPILiExtFctCrc " J1850 CRC";
CM_ SG_ 1092 AplidSwtExtrLiToAPILiExtFctQf " Quality factor";
CM_ SG_ 1092 AplidSwtExtrLiToAPILiExtFctReq1 " Data";
CM_ SG_ 148 ALgtMaxAvlALgtMaxAvl "Maximum longitudinal acceleration capability Maximum longitudinal acceleration capability short horizon";
CM_ SG_ 148 ALgtMaxAvlALgtMaxAvlLong "Maximum longitudinal acceleration capability Maximum Longitudinal acceleration capability long horizon";
CM_ SG_ 148 ALgtMaxAvlChks "Maximum longitudinal acceleration capability Checksum";
CM_ SG_ 148 ALgtMaxAvlCntr "Maximum longitudinal acceleration capability Counter";
CM_ SG_ 148 ALgtMaxAvlDecelLgtMaxAvl "Maximum longitudinal acceleration capability Maximum longitudinal deceleration capability";
CM_ SG_ 148 WhlLockStsChks "Wheel lock and degradation status Checksum";
CM_ SG_ 148 WhlLockStsCntr "Wheel lock and degradation status Counter";
CM_ SG_ 148 WhlLockStsDegradedSts "Wheel lock and degradation status Wheel lock degradation status";
CM_ SG_ 148 WhlLockStsLockSts "Wheel lock and degradation status Wheel lock status";
CM_ SG_ 84 HornActvnReqIf "Horn activating request from the API.

1 = Off
2 = On

";
CM_ SG_ 84 HvSysActvReqExt "Request to activate the high voltage system supply. The request shall be kept TRUE as long as the high voltage supply is needed, and dropped to FALSE when no longer needed. Note that the supply may be kept active even if this request is FALSE.";
CM_ SG_ 84 RainSnsrCmdIf "Used for activating/deactivating the rain sensor function, i.e. automatic wiping.";
CM_ SG_ 84 SnsrClngReqIfClngProg "Used for activating cleaning for a specific camera/sensor.

ClngProg = 0-15 pertains to a specific cleaning program, 0 = Off, 1 = default.

15 = Abort cleaning

SnsrSeld = 0-15 pertains to what camera/sensor is requested to be cleaned. 0 = Off.

2 = Roof mounted sensor pod
3 = Front looking camera (iron mark)
4 = Rear looking camera
5 = Left side view mirror mounted camera(s)
6 = Right side view mirror mounted camera(s)";
CM_ SG_ 84 SnsrClngReqIfSnsrSeld "Used for activating cleaning for a specific camera/sensor.

ClngProg = 0-15 pertains to a specific cleaning program, 0 = Off, 1 = default.

15 = Abort cleaning

SnsrSeld = 0-15 pertains to what camera/sensor is requested to be cleaned. 0 = Off.

2 = Roof mounted sensor pod
3 = Front looking camera (iron mark)
4 = Rear looking camera
5 = Left side view mirror mounted camera(s)
6 = Right side view mirror mounted camera(s)";
CM_ SG_ 84 SwtBeamHiFromAPI "High Beam request.
This signal shall have the same behaviour as the High Beam stalk.";
CM_ SG_ 84 WinWshngCmdIf "Used for requesting front and rear washing.

0: Washing Off
1: Windscreen washing request
2: Rear window washing request";
CM_ SG_ 84 WipgSpdIntlIf "Used for either setting the sensitivity of the rain sensor (when activated) or determining wiping pause time (when wiping is in intermittent mode).
When Autonomous driving mode is activated rain sensor functionality is automatically set to on and rain sensor sensitivity will be given the highest value (i.e. WipgSpdIntlIf = 7).

0 equals lowest rain sensor sensitivity setting/longest interval wiping pause time.
7 equals highest rain sensor sensitivity setting/shortest interval wiping pause time
";
CM_ SG_ 84 WiprFrntReqIfFrntWiprLvrCmd1 "Used for describing different wiping modes  related to wiper stalk position.

0: Initial value (not used)
1: Wiping off
2: Single stroke
3: Intermittent wiping
4: Continuous low speed wiping
5: Continuous high speed wiping Data";
CM_ SG_ 84 WiprFrntReqIfFrntWiprLvrCntr "Used for describing different wiping modes  related to wiper stalk position.

0: Initial value (not used)
1: Wiping off
2: Single stroke
3: Intermittent wiping
4: Continuous low speed wiping
5: Continuous high speed wiping Counter";
CM_ SG_ 84 WiprFrntReqIfFrntWiprLvrCrc "Used for describing different wiping modes  related to wiper stalk position.

0: Initial value (not used)
1: Wiping off
2: Single stroke
3: Intermittent wiping
4: Continuous low speed wiping
5: Continuous high speed wiping J1850 CRC";
CM_ SG_ 84 WiprFrntReqIfFrntWiprLvrQf "Used for describing different wiping modes  related to wiper stalk position.

0: Initial value (not used)
1: Wiping off
2: Single stroke
3: Intermittent wiping
4: Continuous low speed wiping
5: Continuous high speed wiping Quality Factor";
CM_ SG_ 297 CnvincAPIEna "Signal to provide means for External Client to enable the Convenience API by waking TCAM and request TCAM to set up ethernet communication.";
CM_ SG_ 297 OkToClsDoorOkToClsDoorChks " Checksum for Ok to close door signals";
CM_ SG_ 297 OkToClsDoorOkToClsDoorCntr " Counter for Ok to close doors signals";
CM_ SG_ 297 OkToClsDoorOkToClsDoorDrvr " Information whether it is ok to close driver door";
CM_ SG_ 297 OkToClsDoorOkToClsDoorDrvrRe " Information whether it is ok to close rear driver door";
CM_ SG_ 297 OkToClsDoorOkToClsDoorPass " Information whether it is ok to close passenger door";
CM_ SG_ 297 OkToClsDoorOkToClsDoorPassRe " Information whether it is ok to close rear passenger door";
CM_ SG_ 297 OkToOpenDoorOkToOpenDoorChks " Checksum for Ok to open door signals";
CM_ SG_ 297 OkToOpenDoorOkToOpenDoorCntr " Counter for Ok to open doors signals";
CM_ SG_ 297 OkToOpenDoorOkToOpenDoorDrvr " Information whether it is ok to open driver door";
CM_ SG_ 297 OkToOpenDoorOkToOpenDoorDrvrRe " Information whether it is ok to open rear driver door";
CM_ SG_ 297 OkToOpenDoorOkToOpenDoorPass " Information whether it is ok to open passenger door";
CM_ SG_ 297 OkToOpenDoorOkToOpenDoorPassRe " Information whether it is ok to open rear passenger door";
CM_ SG_ 260 HmiAutnmsStsChecksum "Signal from the Autonomy System to the Vehicle Platform, communicating the current AD Mode Status (Unknown, Off, Ready, Not Ready, On, Fault) of the complete system.";
CM_ SG_ 260 HmiAutnmsStsCounter "Signal from the Autonomy System to the Vehicle Platform, communicating the current AD Mode Status (Unknown, Off, Ready, Not Ready, On, Fault) of the complete system.";
CM_ SG_ 260 HmiAutnmsStsHmiAutnmsSts "Signal from the Autonomy System to the Vehicle Platform, communicating the current AD Mode Status (Unknown, Off, Ready, Not Ready, On, Fault) of the complete system.";
CM_ SG_ 260 IDcDcAvlLoSideExt "External DCDC LV side current.";
CM_ SG_ 260 IDcDcAvlMaxLoSideExt "Maximum LV side current from the External DCDC";
CM_ SG_ 260 UDcDcAvlLoSideExt "External DCDC LV side voltage.";
CM_ SG_ 35 ExtDcDcActvnSts2 "Status of Uber DCDC ( 2nd DCDC)";
CM_ SG_ 40 ExtDcDcActvnSts "Status of the external 3rd DCDC (Redundant).";
CM_ SG_ 40 HvIDcDcHiSideExt "The current at the DC/DC connecting the vehicle 400V system to the Autonomous drive system. The current is measured at the high voltage side of the DC/DC. The value of the current shall be the sum of both DCDCs i.e. 2nd DCDC (Backup) and 3rd DCDC (Redundant). ";
CM_ SG_ 40 HvUDcDcHiSideExt "The voltage at the DC/DC connecting the vehicle 400V system to the Autonomous drive system. The voltage is measured at the high voltage side of the DC/DC.";
CM_ SG_ 46 AutnmsDrvStReqAutnmsDrvStReq "(De-)activation request of autonomous drive mode. (De-)activation request of autonomous drive mode.";
CM_ SG_ 46 AutnmsDrvStReqChecksum "(De-)activation request of autonomous drive mode. Checksum";
CM_ SG_ 46 AutnmsDrvStReqCounter "(De-)activation request of autonomous drive mode. Counter";
CM_ SG_ 293 VehOperStReqChecksum "Request for (de-)activation of vehicle operator mode. Checksum";
CM_ SG_ 293 VehOperStReqCounter "Request for (de-)activation of vehicle operator mode. Counter";
CM_ SG_ 293 VehOperStReqVehOperStReq "Request for (de-)activation of vehicle operator mode. Request for (de-)activation of vehicle operator mode";
CM_ SG_ 135 AdDirReqChks "AD direction request Checksum";
CM_ SG_ 135 AdDirReqCntr "AD direction request Counter";
CM_ SG_ 135 AdDirReqDirReq "AD direction request Desired direction request";
CM_ SG_ 135 AdStandStillReqChks "AD standstill request Checksum";
CM_ SG_ 135 AdStandStillReqCntr "AD standstill request Counter";
CM_ SG_ 135 AdStandStillReqReq "AD standstill request Standstill request";
CM_ SG_ 135 VehUsgStReq "External Vehicle usage mode request. Comparable to UsageModes";
CM_ SG_ 280 PrimRoadGradientFromAdBanking "Estimated road gradient, primary channel Road banking";
CM_ SG_ 280 PrimRoadGradientFromAdBankingConf "Estimated road gradient, primary channel Banking confidence";
CM_ SG_ 280 PrimRoadGradientFromAdChks "Estimated road gradient, primary channel E2E checksum";
CM_ SG_ 280 PrimRoadGradientFromAdCntr "Estimated road gradient, primary channel E2E counter";
CM_ SG_ 280 PrimRoadGradientFromAdIncln "Estimated road gradient, primary channel Road inclination";
CM_ SG_ 280 PrimRoadGradientFromAdInclnConf "Estimated road gradient, primary channel Inclination confidence";
CM_ SG_ 288 AdFusedFricEstimnFricEstimn "Fused friction estimation Momentary friction estimate.";
CM_ SG_ 288 AdFusedFricEstimnFricEstimnConf "Fused friction estimation Friction estimate confidence";
CM_ SG_ 288 AdpLiReqFromAPIAhbcActvn " Request to activate AHBC functionality in AD mode";
CM_ SG_ 288 AdpLiReqFromAPIChks " Checksum";
CM_ SG_ 288 AdpLiReqFromAPICntr " Counter";
CM_ SG_ 288 AdpLiReqFromAPIHzrdLiActvnReq " Request to activate hazard lights.";
CM_ SG_ 288 AdpLiReqFromAPIHzrdLiDeactnReq " Request to deactivate hazard lights.";
CM_ SG_ 288 AdpLiReqFromAPIIncrLiRiReq " Request to activate indicator light right.";
CM_ SG_ 288 AdpLiReqFromAPIIndcrLeReq " Request to activate indicator lights left.";
CM_ SG_ 288 SwtExtrLiFromAPILiExtFctCntr "This signal shall represent the Light Switch Module (LSM) position. Counter";
CM_ SG_ 288 SwtExtrLiFromAPILiExtFctCrc "This signal shall represent the Light Switch Module (LSM) position. J1850 CRC";
CM_ SG_ 288 SwtExtrLiFromAPILiExtFctQf "This signal shall represent the Light Switch Module (LSM) position. Quality factor";
CM_ SG_ 288 SwtExtrLiFromAPILiExtFctReq1 "This signal shall represent the Light Switch Module (LSM) position. Data";
CM_ SG_ 1091 ActvnOfHndlDoorLiFromAPIHndlDoorLiDrvr " Driver door handle light";
CM_ SG_ 1091 ActvnOfHndlDoorLiFromAPIHndlDoorLiDrvrRe " Rear driver door handle light";
CM_ SG_ 1091 ActvnOfHndlDoorLiFromAPIHndlDoorLiPass " Passenger door handle light";
CM_ SG_ 1091 ActvnOfHndlDoorLiFromAPIHndlDoorLiPassRe " Rear passenger door handle light";
CM_ SG_ 150 AdFreeDstChks " E2E Checksum";
CM_ SG_ 150 AdFreeDstCntr " E2E counter";
CM_ SG_ 150 AdFreeDstFreeDstFwd " Free distance in forward direction";
CM_ SG_ 150 AdFreeDstFreeDstRvs " Free distance in reverse direction";
CM_ SG_ 150 AdSetSpd "Set speed for autonomous drive. ";
CM_ SG_ 150 AdWhlLockReqChks "AD request to lock wheels Checksum";
CM_ SG_ 150 AdWhlLockReqCntr "AD request to lock wheels Counter";
CM_ SG_ 150 AdWhlLockReqNoReqApplyRel "AD request to lock wheels NoReqApplyRel";
CM_ SG_ 86 AdNomALgtReqGroupSafeALgtNomReqMax "Nominal longitudinal acceleration request Nominal acceleration req from HAD.";
CM_ SG_ 86 AdNomALgtReqGroupSafeALgtNomReqMin "Nominal longitudinal acceleration request Nominal acceleration req from HAD.";
CM_ SG_ 86 AdNomALgtReqGroupSafeChks "Nominal longitudinal acceleration request E2E Checksum";
CM_ SG_ 86 AdNomALgtReqGroupSafeCntr "Nominal longitudinal acceleration request E2E Counter";
CM_ SG_ 86 AdNomALgtReqGroupSafeNegLimForJerk "Nominal longitudinal acceleration request Limit of maximum allowed negative jerk (acceleration rate of change)";
CM_ SG_ 86 AdNomALgtReqGroupSafePosLimForJerk "Nominal longitudinal acceleration request Limit of maximum allowed positive jerk (acceleration rate of change)";
CM_ SG_ 87 AdPrimALgtLimReqGroupSafeALgtMaxReq "Safety critical acceleration request from HAD. Safety critical acceleration request from HAD.";
CM_ SG_ 87 AdPrimALgtLimReqGroupSafeALgtMinReq "Safety critical acceleration request from HAD. Safety critical acceleration request from HAD.";
CM_ SG_ 87 AdPrimALgtLimReqGroupSafeChks "Safety critical acceleration request from HAD. E2E checksum";
CM_ SG_ 87 AdPrimALgtLimReqGroupSafeCntr "Safety critical acceleration request from HAD. E2E Counter";
BA_DEF_ BO_ "GenMsgCycleTime" INT 0 65536; // [ms]
BA_DEF_ BO_ "GenMsgDelayTime" INT 0 65536; // [ms]
BA_DEF_ BO_ "GenMsgSendType" ENUM "cyclic", "spontaneous", "not-used", "not-used", "not-used", "cyclicAndSpontaneous", "not-used", "cyclicIfActive", "NoMsgSendType"; // [us]
BA_DEF_ BO_ "GenMsgStartDelayTime" INT 0 65536; // [ms]
BA_DEF_ SG_ "GenSigSendType" ENUM "Cyclic","OnWrite","OnWriteWithRepetition","OnChange","OnChangeWithRepetition","IfActive","IfActiveWithRepetition","NoSigSendType";
BA_DEF_ SG_ "GenSigStartValue" HEX 0 80000000;
BA_DEF_ BO_ "GenMsgILSupport" ENUM "No","Yes";
BA_DEF_ BO_ "NmAsrMessage" ENUM "No","Yes";
BA_DEF_ SG_ "GenSigFuncType" ENUM "NoFunction","n/a","n/a","n/a","n/a","n/a","n/a","n/a","n/a","n/a","n/a","n/a","n/a","n/a","n/a","CHK","CNTR","n/a","n/a","n/a","CNTR_AR_01","CRC_AR_01_BOTH","CRC_AR_01_ALT","CRC_AR_01_LOW","CRC_AR_01_NIBBLE","CNTR_AR_04","CRC_AR_04A","CNTR_AR_05","CRC_AR_05";
BA_DEF_ SG_ "GenSigDataID" STRING;
BA_DEF_ SG_ "SigGroup" STRING;
BA_DEF_DEF_ "GenSigStartValue" 0;
BA_DEF_DEF_ "GenSigSendType" "NoSigSendType";
BA_DEF_DEF_ "GenMsgCycleTime" 0;
BA_DEF_DEF_ "GenMsgDelayTime" 0;
BA_DEF_DEF_ "GenMsgStartDelayTime" 0;
BA_DEF_DEF_ "GenMsgSendType" "NoMsgSendType";
BA_DEF_DEF_ "GenMsgILSupport" "Yes";
BA_DEF_DEF_ "NmAsrMessage" "No";
BA_DEF_DEF_ "GenSigFuncType" "NoFunction";
BA_DEF_DEF_ "GenSigDataID" "";
BA_DEF_DEF_ "SigGroup" "";
// Frame: VCU1Mid3CanFr14
BA_ "GenMsgCycleTime" BO_ 1120 1100.000;
BA_ "GenMsgSendType" BO_ 1120 0;
// Frame: VCU1Mid3CanFr15
BA_ "GenMsgCycleTime" BO_ 1084 800.000;
BA_ "GenMsgSendType" BO_ 1084 0;
// Frame: VCU1Mid3CanFr16
BA_ "GenMsgCycleTime" BO_ 512 400.000;
BA_ "GenMsgSendType" BO_ 512 0;
// Frame: VCU1Mid3CanFr17
BA_ "GenMsgCycleTime" BO_ 384 300.000;
BA_ "GenMsgSendType" BO_ 384 0;
// Frame: VCU1Mid3CanFr18
BA_ "GenMsgCycleTime" BO_ 119 20.000;
BA_ "GenMsgSendType" BO_ 119 0;
// Frame: VCU1Mid3CanFr19
BA_ "GenMsgCycleTime" BO_ 104 45.000;
BA_ "GenMsgSendType" BO_ 104 0;
// Frame: VCU1Mid3CanFr20
BA_ "GenMsgCycleTime" BO_ 88 20.000;
BA_ "GenMsgSendType" BO_ 88 0;
// Frame: VCU1Mid3CanFr21
BA_ "GenMsgCycleTime" BO_ 89 20.000;
BA_ "GenMsgSendType" BO_ 89 0;
// Frame: VCU1Mid3CanFr22
BA_ "GenMsgCycleTime" BO_ 133 20.000;
BA_ "GenMsgSendType" BO_ 133 0;
// Frame: VCU1Mid3CanFr23
BA_ "GenMsgCycleTime" BO_ 352 280.000;
BA_ "GenMsgSendType" BO_ 352 0;
// Frame: VCU1Mid3CanFr24
BA_ "GenMsgCycleTime" BO_ 120 15.000;
BA_ "GenMsgSendType" BO_ 120 0;
// Frame: VCU1Mid3CanFr25
BA_ "GenMsgCycleTime" BO_ 391 160.000;
BA_ "GenMsgSendType" BO_ 391 0;
// Frame: VCU1Mid3CanFr28
BA_ "GenMsgCycleTime" BO_ 1136 1100.000;
BA_ "GenMsgSendType" BO_ 1136 0;
// Frame: VCU1Mid3CanFr29
BA_ "GenMsgCycleTime" BO_ 917 440.000;
BA_ "GenMsgSendType" BO_ 917 0;
// Frame: VCU1Mid3CanFr30
BA_ "GenMsgCycleTime" BO_ 83 15.000;
BA_ "GenMsgSendType" BO_ 83 0;
// Frame: VCU1Mid3CanFr31
BA_ "GenMsgCycleTime" BO_ 131 30.000;
BA_ "GenMsgSendType" BO_ 131 0;
// Frame: VCU1Mid3CanFr32
BA_ "GenMsgCycleTime" BO_ 1104 920.000;
BA_ "GenMsgSendType" BO_ 1104 0;
// Frame: VCU1Mid3CanFr33
BA_ "GenMsgCycleTime" BO_ 311 275.000;
BA_ "GenMsgSendType" BO_ 311 0;
// Frame: VCU1Mid3CanFr34
BA_ "GenMsgCycleTime" BO_ 97 45.000;
BA_ "GenMsgSendType" BO_ 97 0;
// Frame: VCU1Mid3CanFr35
BA_ "GenMsgCycleTime" BO_ 1092 840.000;
BA_ "GenMsgSendType" BO_ 1092 0;
// Frame: VCU1Mid3CanFr36
BA_ "GenMsgCycleTime" BO_ 148 20.000;
BA_ "GenMsgSendType" BO_ 148 0;
// Frame: VIMMid3CanFr01
BA_ "GenMsgCycleTime" BO_ 84 15.000;
BA_ "GenMsgSendType" BO_ 84 0;
// Frame: VIMMid3CanFr02
BA_ "GenMsgCycleTime" BO_ 297 260.000;
BA_ "GenMsgSendType" BO_ 297 0;
// Frame: VIMMid3CanFr03
BA_ "GenMsgCycleTime" BO_ 296 260.000;
BA_ "GenMsgSendType" BO_ 296 0;
// Frame: VIMMid3CanFr04
BA_ "GenMsgCycleTime" BO_ 260 45.000;
BA_ "GenMsgSendType" BO_ 260 0;
// Frame: VIMMid3CanFr05
BA_ "GenMsgCycleTime" BO_ 35 15.000;
BA_ "GenMsgSendType" BO_ 35 0;
// Frame: VIMMid3CanFr06
BA_ "GenMsgCycleTime" BO_ 40 10.000;
BA_ "GenMsgSendType" BO_ 40 0;
// Frame: VIMMid3CanFr07
BA_ "GenMsgCycleTime" BO_ 46 10.000;
BA_ "GenMsgSendType" BO_ 46 0;
// Frame: VIMMid3CanFr08
BA_ "GenMsgCycleTime" BO_ 293 200.000;
BA_ "GenMsgSendType" BO_ 293 0;
// Frame: VIMMid3CanFr09
BA_ "GenMsgCycleTime" BO_ 135 30.000;
BA_ "GenMsgSendType" BO_ 135 0;
// Frame: VIMMid3CanFr10
BA_ "GenMsgCycleTime" BO_ 280 60.000;
BA_ "GenMsgSendType" BO_ 280 0;
// Frame: VIMMid3CanFr11
BA_ "GenMsgCycleTime" BO_ 288 80.000;
BA_ "GenMsgSendType" BO_ 288 0;
// Frame: VIMMid3CanFr12
BA_ "GenMsgCycleTime" BO_ 1091 840.000;
BA_ "GenMsgSendType" BO_ 1091 0;
// Frame: VIMMid3CanFr13
BA_ "GenMsgCycleTime" BO_ 150 80.000;
BA_ "GenMsgSendType" BO_ 150 0;
// Frame: VIMMid3CanFr14
BA_ "GenMsgCycleTime" BO_ 86 10.000;
BA_ "GenMsgSendType" BO_ 86 0;
// Frame: VIMMid3CanFr15
BA_ "GenMsgCycleTime" BO_ 87 10.000;
BA_ "GenMsgSendType" BO_ 87 0;
// Frame: Vcu1Mid3CanNmFr
BA_ "GenMsgDelayTime" BO_ 1283 20.000;
BA_ "GenMsgSendType" BO_ 1283 1;
// Frame: Vcu1ToAllFuncMid3DiagReqFrame
BA_ "GenMsgDelayTime" BO_ 2047 5.000;
BA_ "GenMsgSendType" BO_ 2047 1;
// Frame: VimMid3CanNmFr
BA_ "GenMsgDelayTime" BO_ 1288 20.000;
BA_ "GenMsgSendType" BO_ 1288 1;
BA_ "GenMsgILSupport" BO_ 1283 0;
BA_ "GenMsgILSupport" BO_ 1288 0;
BA_ "NmAsrMessage" BO_ 1283 1;
BA_ "NmAsrMessage" BO_ 1288 1;
BA_ "GenSigStartValue" SG_ 148 ALgtMaxAvlALgtMaxAvl 30;
BA_ "GenSigStartValue" SG_ 148 ALgtMaxAvlALgtMaxAvlLong 30;
BA_ "GenSigDataID" SG_ 148 ALgtMaxAvlChks "0x1CA";
BA_ "GenSigFuncType" SG_ 148 ALgtMaxAvlChks 15;
BA_ "GenSigFuncType" SG_ 148 ALgtMaxAvlCntr 16;
BA_ "GenSigDataID" SG_ 119 AccrPedlPsdAccrPedlPsdChks "0x48";
BA_ "GenSigFuncType" SG_ 119 AccrPedlPsdAccrPedlPsdChks 15;
BA_ "GenSigFuncType" SG_ 119 AccrPedlPsdAccrPedlPsdCntr 16;
BA_ "GenSigDataID" SG_ 135 AdDirReqChks "0x1C4";
BA_ "GenSigFuncType" SG_ 135 AdDirReqChks 15;
BA_ "GenSigFuncType" SG_ 135 AdDirReqCntr 16;
BA_ "GenSigDataID" SG_ 150 AdFreeDstChks "0x1C7";
BA_ "GenSigFuncType" SG_ 150 AdFreeDstChks 15;
BA_ "GenSigFuncType" SG_ 150 AdFreeDstCntr 16;
BA_ "GenSigStartValue" SG_ 86 AdNomALgtReqGroupSafeALgtNomReqMax 3840;
BA_ "GenSigDataID" SG_ 86 AdNomALgtReqGroupSafeChks "0x1C1";
BA_ "GenSigFuncType" SG_ 86 AdNomALgtReqGroupSafeChks 15;
BA_ "GenSigFuncType" SG_ 86 AdNomALgtReqGroupSafeCntr 16;
BA_ "GenSigStartValue" SG_ 86 AdNomALgtReqGroupSafePosLimForJerk 4000;
BA_ "GenSigStartValue" SG_ 87 AdPrimALgtLimReqGroupSafeALgtMaxReq 3840;
BA_ "GenSigDataID" SG_ 87 AdPrimALgtLimReqGroupSafeChks "0x1C2";
BA_ "GenSigFuncType" SG_ 87 AdPrimALgtLimReqGroupSafeChks 15;
BA_ "GenSigFuncType" SG_ 87 AdPrimALgtLimReqGroupSafeCntr 16;
BA_ "GenSigDataID" SG_ 133 AdSecBrkActvnGroupSafeChks "0x221";
BA_ "GenSigFuncType" SG_ 133 AdSecBrkActvnGroupSafeChks 15;
BA_ "GenSigFuncType" SG_ 133 AdSecBrkActvnGroupSafeCntr 16;
BA_ "GenSigDataID" SG_ 135 AdStandStillReqChks "0x557";
BA_ "GenSigFuncType" SG_ 135 AdStandStillReqChks 15;
BA_ "GenSigFuncType" SG_ 135 AdStandStillReqCntr 16;
BA_ "GenSigDataID" SG_ 150 AdWhlLockReqChks "0x647";
BA_ "GenSigFuncType" SG_ 150 AdWhlLockReqChks 15;
BA_ "GenSigFuncType" SG_ 150 AdWhlLockReqCntr 16;
BA_ "GenSigDataID" SG_ 288 AdpLiReqFromAPIChks "0x72E";
BA_ "GenSigFuncType" SG_ 288 AdpLiReqFromAPIChks 15;
BA_ "GenSigFuncType" SG_ 288 AdpLiReqFromAPICntr 16;
BA_ "GenSigStartValue" SG_ 1092 AplidSwtExtrLiToAPILiExtFctQf 1;
BA_ "GenSigDataID" SG_ 83 AutnmsDrvModMngtExtSafeChecksum "0x2AD";
BA_ "GenSigFuncType" SG_ 83 AutnmsDrvModMngtExtSafeChecksum 21;
BA_ "GenSigFuncType" SG_ 83 AutnmsDrvModMngtExtSafeCounter 20;
BA_ "GenSigDataID" SG_ 46 AutnmsDrvStReqChecksum "0x1F7";
BA_ "GenSigFuncType" SG_ 46 AutnmsDrvStReqChecksum 21;
BA_ "GenSigFuncType" SG_ 46 AutnmsDrvStReqCounter 20;
BA_ "GenSigStartValue" SG_ 917 BattIExt 4100;
BA_ "GenSigStartValue" SG_ 917 BattUExt 1520;
BA_ "GenSigStartValue" SG_ 1084 BltLockStAtRowSecMidForBltLockEquid 1;
BA_ "GenSigStartValue" SG_ 1084 BltLockStAtRowSecMidForBltLockSts 1;
BA_ "GenSigDataID" SG_ 83 BrkDegradedChks "0x1CB";
BA_ "GenSigFuncType" SG_ 83 BrkDegradedChks 15;
BA_ "GenSigFuncType" SG_ 83 BrkDegradedCntr 16;
BA_ "GenSigDataID" SG_ 133 BrkFricTqTotAtWhlsActBrkFricTqTotAtWhlsActChks "0x7B";
BA_ "GenSigFuncType" SG_ 133 BrkFricTqTotAtWhlsActBrkFricTqTotAtWhlsActChks 15;
BA_ "GenSigFuncType" SG_ 133 BrkFricTqTotAtWhlsActBrkFricTqTotAtWhlsActCntr 16;
BA_ "GenSigDataID" SG_ 119 BrkPedlPsdChks "0x38";
BA_ "GenSigFuncType" SG_ 119 BrkPedlPsdChks 15;
BA_ "GenSigFuncType" SG_ 119 BrkPedlPsdCntr 16;
BA_ "GenSigStartValue" SG_ 119 BrkPedlPsdQf 1;
BA_ "GenSigStartValue" SG_ 1104 CornrStfnCornrStfnQly 1;
BA_ "GenSigStartValue" SG_ 391 DrvrPrsnt 1;
BA_ "GenSigStartValue" SG_ 391 DrvrPrsntQf 1;
BA_ "GenSigDataID" SG_ 391 DrvrPrsntStsDrvrPrsntChks "0x79";
BA_ "GenSigFuncType" SG_ 391 DrvrPrsntStsDrvrPrsntChks 15;
BA_ "GenSigFuncType" SG_ 391 DrvrPrsntStsDrvrPrsntCntr 16;
BA_ "GenSigStartValue" SG_ 391 EgyAvlChrgTot 10;
BA_ "GenSigStartValue" SG_ 391 EgyAvlDchaTot 10;
BA_ "GenSigStartValue" SG_ 131 EstimdCoastALgtCpby 30;
BA_ "GenSigStartValue" SG_ 260 HmiAutnmsStsHmiAutnmsSts 1;
BA_ "GenSigStartValue" SG_ 40 HvIDcDcHiSideExt 4100;
BA_ "GenSigStartValue" SG_ 1104 LgtStfnLgtStfnQly 1;
BA_ "GenSigDataID" SG_ 297 OkToClsDoorOkToClsDoorChks "0x411";
BA_ "GenSigFuncType" SG_ 297 OkToClsDoorOkToClsDoorChks 15;
BA_ "GenSigFuncType" SG_ 297 OkToClsDoorOkToClsDoorCntr 16;
BA_ "GenSigDataID" SG_ 297 OkToOpenDoorOkToOpenDoorChks "0x410";
BA_ "GenSigFuncType" SG_ 297 OkToOpenDoorOkToOpenDoorChks 15;
BA_ "GenSigFuncType" SG_ 297 OkToOpenDoorOkToOpenDoorCntr 16;
BA_ "GenSigDataID" SG_ 119 OvrdDecelByDrvrOvrdDecelByDrvrChks "0x6E";
BA_ "GenSigFuncType" SG_ 119 OvrdDecelByDrvrOvrdDecelByDrvrChks 15;
BA_ "GenSigFuncType" SG_ 119 OvrdDecelByDrvrOvrdDecelByDrvrCntr 16;
BA_ "GenSigDataID" SG_ 280 PrimRoadGradientFromAdChks "0x1DC";
BA_ "GenSigFuncType" SG_ 280 PrimRoadGradientFromAdChks 15;
BA_ "GenSigFuncType" SG_ 280 PrimRoadGradientFromAdCntr 16;
BA_ "GenSigStartValue" SG_ 120 PrimSteerMotTqSteerMotTqQf 1;
BA_ "GenSigStartValue" SG_ 512 PrpsnErrIndcnReq 1;
BA_ "GenSigDataID" SG_ 1136 SftyDecelGroupSafeChks "0x4C";
BA_ "GenSigFuncType" SG_ 1136 SftyDecelGroupSafeChks 15;
BA_ "GenSigFuncType" SG_ 1136 SftyDecelGroupSafeCntr 16;
BA_ "GenSigDataID" SG_ 97 StandStillMgrStsForHldSafeChks "0x1D0";
BA_ "GenSigFuncType" SG_ 97 StandStillMgrStsForHldSafeChks 15;
BA_ "GenSigFuncType" SG_ 97 StandStillMgrStsForHldSafeCntr 16;
BA_ "GenSigStartValue" SG_ 352 TirePValFrntLeTirePabsltValQF 1;
BA_ "GenSigStartValue" SG_ 352 TirePValFrntRiTirePAbsltValQF 1;
BA_ "GenSigStartValue" SG_ 352 TirePValReLeTirePAbsltValQF 1;
BA_ "GenSigStartValue" SG_ 352 TirePValReRiTirePAbsltValQF 1;
BA_ "GenSigStartValue" SG_ 1084 TireRdEstimd 204.8005243;
BA_ "GenSigStartValue" SG_ 311 TireRdEstimdAtWhlsFrLe 512.0013107;
BA_ "GenSigStartValue" SG_ 311 TireRdEstimdAtWhlsFrRi 512.0013107;
BA_ "GenSigStartValue" SG_ 311 TireRdEstimdAtWhlsReLe 512.0013107;
BA_ "GenSigStartValue" SG_ 311 TireRdEstimdAtWhlsReRi 512.0013107;
BA_ "GenSigStartValue" SG_ 1084 TireRdEstimdQly 1;
BA_ "GenSigDataID" SG_ 131 VehOpReqInVehDynGroupSafeChks "0x1FC";
BA_ "GenSigFuncType" SG_ 131 VehOpReqInVehDynGroupSafeChks 15;
BA_ "GenSigFuncType" SG_ 131 VehOpReqInVehDynGroupSafeCntr 16;
BA_ "GenSigDataID" SG_ 293 VehOperStReqChecksum "0x1F6";
BA_ "GenSigFuncType" SG_ 293 VehOperStReqChecksum 21;
BA_ "GenSigFuncType" SG_ 293 VehOperStReqCounter 20;
BA_ "GenSigDataID" SG_ 148 WhlLockStsChks "0x1C9";
BA_ "GenSigFuncType" SG_ 148 WhlLockStsChks 15;
BA_ "GenSigFuncType" SG_ 148 WhlLockStsCntr 16;
VAL_ 1120 CllsnAidSnvtySeldPen 0 "IdPen_ProfUkwn" 1 "IdPen_Prof1" 2 "IdPen_Prof2" 3 "IdPen_Prof3" 4 "IdPen_Prof4" 5 "IdPen_Prof5" 6 "IdPen_Prof6" 7 "IdPen_Prof7" 8 "IdPen_Prof8" 9 "IdPen_Prof9" 10 "IdPen_Prof10" 11 "IdPen_Prof11" 12 "IdPen_Prof12" 13 "IdPen_Prof13" 14 "IdPen_Resd14" 15 "IdPen_ProfAll";
VAL_ 1120 CllsnAidSnvtySeldSts 0 "Snvty1_NotInUse" 1 "Snvty1_LoSnvty" 2 "Snvty1_NormSnvty" 3 "Snvty1_HiSnvty";
VAL_ 1120 CllsnFwdWarnReq 0 "OnOff1_Off" 1 "OnOff1_On";
VAL_ 1120 CllsnThreat 0 "CllsnThreat1_Ukwn" 1 "CllsnThreat1_ThreatLo" 2 "CllsnThreat1_ThreatMed" 3 "CllsnThreat1_ThreatHi";
VAL_ 1120 CnclReqForCrsCtrl 0 "CnclReqCrit1_NotAllwd1" 1 "CnclReqCrit1_NoCnclReq" 2 "CnclReqCrit1_CnclReq" 3 "CnclReqCrit1_NotAllwd2";
VAL_ 1120 IndcrDisp1WdSts 0 "IndcrSts1_Off" 1 "IndcrSts1_LeOn" 2 "IndcrSts1_RiOn" 3 "IndcrSts1_LeAndRiOn";
VAL_ 1120 IndcrTurnSts1WdSts 0 "IndcrSts1_Off" 1 "IndcrSts1_LeOn" 2 "IndcrSts1_RiOn" 3 "IndcrSts1_LeAndRiOn";
VAL_ 1120 SrvRqrdForCllsnAid 0 "OnOff1_Off" 1 "OnOff1_On";
VAL_ 1084 BeamHiIndcnDisp 0 "OnOff1_Off" 1 "OnOff1_On";
VAL_ 1084 BltLockStAtRowSecMidForBltLockEquid 0 "CptEquid_Equid" 1 "CptEquid_NotEquid";
VAL_ 1084 BltLockStAtRowSecMidForBltLockSt1 0 "BltLockSt1_Unlock" 1 "BltLockSt1_Lock";
VAL_ 1084 BltLockStAtRowSecMidForBltLockSts 0 "DevErrSts2_NoFlt" 1 "DevErrSts2_Flt";
VAL_ 1084 FltIndcrTurnLeFrnt 0 "DevErrSts2_NoFlt" 1 "DevErrSts2_Flt";
VAL_ 1084 FltIndcrTurnLeRe 0 "DevErrSts2_NoFlt" 1 "DevErrSts2_Flt";
VAL_ 1084 FltIndcrTurnRiFrnt 0 "DevErrSts2_NoFlt" 1 "DevErrSts2_Flt";
VAL_ 1084 FltIndcrTurnRiRe 0 "DevErrSts2_NoFlt" 1 "DevErrSts2_Flt";
VAL_ 1084 FltLiRvsg 0 "DevErrSts2_NoFlt" 1 "DevErrSts2_Flt";
VAL_ 1084 FltOfBeamHiLe 0 "DevErrSts2_NoFlt" 1 "DevErrSts2_Flt";
VAL_ 1084 FltOfBeamHiRi 0 "DevErrSts2_NoFlt" 1 "DevErrSts2_Flt";
VAL_ 1084 FltOfBeamLoLe 0 "DevErrSts2_NoFlt" 1 "DevErrSts2_Flt";
VAL_ 1084 FltOfBeamLoRi 0 "DevErrSts2_NoFlt" 1 "DevErrSts2_Flt";
VAL_ 1084 FltOfBrkLiHiMntd 0 "DevErrSts2_NoFlt" 1 "DevErrSts2_Flt";
VAL_ 1084 FltOfBrkLiLe 0 "DevErrSts2_NoFlt" 1 "DevErrSts2_Flt";
VAL_ 1084 FltOfBrkLiRi 0 "DevErrSts2_NoFlt" 1 "DevErrSts2_Flt";
VAL_ 1084 FltOfFogLiFrnt 0 "DevErrSts2_NoFlt" 1 "DevErrSts2_Flt";
VAL_ 1084 FltOfLiPosnFrntLe 0 "DevErrSts2_NoFlt" 1 "DevErrSts2_Flt";
VAL_ 1084 FltOfLiPosnFrntRi 0 "DevErrSts2_NoFlt" 1 "DevErrSts2_Flt";
VAL_ 1084 FltOfPlateNr 0 "DevErrSts2_NoFlt" 1 "DevErrSts2_Flt";
VAL_ 1084 FltOfPosnReLe 0 "DevErrSts2_NoFlt" 1 "DevErrSts2_Flt";
VAL_ 1084 FltOfPosnReRi 0 "DevErrSts2_NoFlt" 1 "DevErrSts2_Flt";
VAL_ 1084 HdlampSysFailr 0 "DevErrSts2_NoFlt" 1 "DevErrSts2_Flt";
VAL_ 1084 SysBrkLiFailr 0 "DevErrSts2_NoFlt" 1 "DevErrSts2_Flt";
VAL_ 1084 SysDirIndcnFailr 0 "DevErrSts2_NoFlt" 1 "DevErrSts2_Flt";
VAL_ 1084 TireRdEstimdQly 0 "Qly2_Flt" 1 "Qly2_NoInfo" 2 "Qly2_Vld";
VAL_ 512 AsySftyDecelEnadByVehDyn 0 "AsySftyDecelEnadByVehDyn1_AsyBrkgNotAllwd" 1 "AsySftyDecelEnadByVehDyn1_AsyBrkgAllwd";
VAL_ 512 EngOilPWarn 0 "EngOilPWarn1_EngOilPOk" 1 "EngOilPWarn1_EngOilPNotOk";
VAL_ 512 InhbOfAsySftyDecelByVehDyn 0 "InhbOfAsySftyDecelByVehDyn1_AsySftyBrkgNotDendByBrk" 1 "InhbOfAsySftyDecelByVehDyn1_AsySftyBrkgDendByBrk";
VAL_ 512 PrpsnErrIndcnReq 1 "MilSt_Off" 2 "MilSt_On" 3 "MilSt_Blink";
VAL_ 512 RoadLoadNomCoeffSts 0 "Boolean_FALSE" 1 "Boolean_TRUE";
VAL_ 512 TankFlapSts 0 "DoorSts2_Ukwn" 1 "DoorSts2_Opend" 2 "DoorSts2_Clsd";
VAL_ 512 TrsmFltIndcn 0 "TrsmFltIndcn1_TrsmFltIndcnNoReq" 1 "TrsmFltIndcn1_TrsmFltIndcn1" 2 "TrsmFltIndcn1_TrsmFltIndcn2" 3 "TrsmFltIndcn1_TrsmFltIndcn3" 4 "TrsmFltIndcn1_TrsmFltIndcn4" 5 "TrsmFltIndcn1_TrsmFltIndcn5" 6 "TrsmFltIndcn1_TrsmFltIndcn6" 7 "TrsmFltIndcn1_TrsmFltIndcn7" 8 "TrsmFltIndcn1_TrsmFltIndcn8" 9 "TrsmFltIndcn1_TrsmFltIndcn9" 10 "TrsmFltIndcn1_TrsmFltIndcn10" 11 "TrsmFltIndcn1_TrsmFltIndcn11" 12 "TrsmFltIndcn1_TrsmFltIndcn12" 13 "TrsmFltIndcn1_TrsmFltIndcn13" 14 "TrsmFltIndcn1_TrsmFltIndcn14" 15 "TrsmFltIndcn1_TrsmFltIndcn15" 16 "TrsmFltIndcn1_TrsmFltIndcn16" 17 "TrsmFltIndcn1_TrsmFltIndcn17" 18 "TrsmFltIndcn1_TrsmFltIndcn18" 19 "TrsmFltIndcn1_TrsmFltIndcn19" 20 "TrsmFltIndcn1_TrsmFltIndcn20" 21 "TrsmFltIndcn1_TrsmFltIndcn21" 22 "TrsmFltIndcn1_TrsmFltIndcn22" 23 "TrsmFltIndcn1_TrsmFltIndcn23" 24 "TrsmFltIndcn1_TrsmFltIndcn24" 25 "TrsmFltIndcn1_TrsmFltIndcn25" 26 "TrsmFltIndcn1_TrsmFltIndcn26" 27 "TrsmFltIndcn1_TrsmFltIndcn27" 28 "TrsmFltIndcn1_TrsmFltIndcn28" 29 "TrsmFltIndcn1_TrsmFltIndcn29" 30 "TrsmFltIndcn1_TrsmFltIndcn30" 31 "TrsmFltIndcn1_TrsmFltIndcn31";
VAL_ 384 ALnchTiDly3Qf 0 "Qf1_DevOfDataUndefd" 1 "Qf1_DataTmpUndefdAndEvlnInProgs" 2 "Qf1_DevOfDataNotWithinRngAllwd" 3 "Qf1_DataCalcdWithDevDefd";
VAL_ 384 AlrmSt 0 "AlrmSt_Disarmd" 1 "AlrmSt_Armd" 2 "AlrmSt_Actv";
VAL_ 384 AlrmTrgSrc 0 "AlrmTrgSrc_NoTrigSrc" 1 "AlrmTrgSrc_SnsrSoundrBattBacked" 2 "AlrmTrgSrc_SnsrIncln" 3 "AlrmTrgSrc_SnsrIntrScanr" 4 "AlrmTrgSrc_Hood" 5 "AlrmTrgSrc_Tr" 6 "AlrmTrgSrc_DoorDrvr" 7 "AlrmTrgSrc_DoorPass" 8 "AlrmTrgSrc_DoorReLe" 9 "AlrmTrgSrc_DoorReRi" 10 "AlrmTrgSrc_VehImobnInvld";
VAL_ 384 DoorDrvrReSts 0 "DoorSts2_Ukwn" 1 "DoorSts2_Opend" 2 "DoorSts2_Clsd";
VAL_ 384 DoorDrvrSts 0 "DoorSts2_Ukwn" 1 "DoorSts2_Opend" 2 "DoorSts2_Clsd";
VAL_ 384 DoorPassReSts 0 "DoorSts2_Ukwn" 1 "DoorSts2_Opend" 2 "DoorSts2_Clsd";
VAL_ 384 DoorPassSts 0 "DoorSts2_Ukwn" 1 "DoorSts2_Opend" 2 "DoorSts2_Clsd";
VAL_ 384 EngOilLvlSts 0 "EngOilLvlSts1_OilLvlOk" 1 "EngOilLvlSts1_OilLvlLo1" 2 "EngOilLvlSts1_OilLvlLo2" 3 "EngOilLvlSts1_OilLvlHi" 4 "EngOilLvlSts1_OilLvlSrvRqrd" 5 "EngOilLvlSts1_Resd";
VAL_ 384 HoodSts 0 "DoorSts2_Ukwn" 1 "DoorSts2_Opend" 2 "DoorSts2_Clsd";
VAL_ 384 SnsrInclnFailr 0 "SnsrInclnFailr_NoFailr" 1 "SnsrInclnFailr_Failr";
VAL_ 384 SnsrIntrScanrFailr 0 "SnsrIntrScanrFailr_NoFailr" 1 "SnsrIntrScanrFailr_Failr";
VAL_ 384 SnsrSoundrBattBackedFailr 0 "SnsrSoundrBattBackedFailr_NoFailr" 1 "SnsrSoundrBattBackedFailr_Failr";
VAL_ 384 TrSts 0 "DoorSts2_Ukwn" 1 "DoorSts2_Opend" 2 "DoorSts2_Clsd";
VAL_ 119 AccrPedlPsdAccrPedlPsd 0 "NoYes1_No" 1 "NoYes1_Yes";
VAL_ 119 AccrPedlPsdAccrPedlPsdSts 0 "NoYes1_No" 1 "NoYes1_Yes";
VAL_ 119 BrkPedlNotPsdSafe 0 "NoYes1_No" 1 "NoYes1_Yes";
VAL_ 119 BrkPedlPsd 0 "NoYes1_No" 1 "NoYes1_Yes";
VAL_ 119 BrkPedlPsdQf 0 "GenQf1_UndefindDataAccur" 1 "GenQf1_TmpUndefdData" 2 "GenQf1_DataAccurNotWithinSpcn" 3 "GenQf1_AccurData";
VAL_ 119 HvSysActvStsExt1 0 "Boolean_FALSE" 1 "Boolean_TRUE";
VAL_ 119 OvrdDecelByDrvrOvrdDecelByDrvr 0 "NoYes1_No" 1 "NoYes1_Yes";
VAL_ 104 PtGearAct 0 "PtGearAct1_Neut" 1 "PtGearAct1_Gear1" 2 "PtGearAct1_Gear2" 3 "PtGearAct1_Gear3" 4 "PtGearAct1_Gear4" 5 "PtGearAct1_Gear5" 6 "PtGearAct1_Gear6" 7 "PtGearAct1_Gear7" 8 "PtGearAct1_Gear8" 9 "PtGearAct1_Gear9" 10 "PtGearAct1_Gear10" 11 "PtGearAct1_Gear11" 12 "PtGearAct1_Gear12" 13 "PtGearAct1_Gear13" 14 "PtGearAct1_Ukwn" 15 "PtGearAct1_Rvs";
VAL_ 104 TirePWarnFrntRiTirePWarn 0 "TirePWarn_NoWarn" 1 "TirePWarn_SoftWarn" 2 "TirePWarn_HardWarn" 3 "TirePWarn_ResdWarn";
VAL_ 104 TirePWarnFrntRiTirePWarnType 0 "TirePWarnType_NoWarn" 1 "TirePWarnType_iTPMSWarn" 2 "TirePWarnType_dTPMSWarn" 3 "TirePWarnType_FullWarn";
VAL_ 104 TirePWarnReLeTirePWarn 0 "TirePWarn_NoWarn" 1 "TirePWarn_SoftWarn" 2 "TirePWarn_HardWarn" 3 "TirePWarn_ResdWarn";
VAL_ 104 TirePWarnReLeTirePWarnType 0 "TirePWarnType_NoWarn" 1 "TirePWarnType_iTPMSWarn" 2 "TirePWarnType_dTPMSWarn" 3 "TirePWarnType_FullWarn";
VAL_ 104 TirePWarnReRiTirePWarn 0 "TirePWarn_NoWarn" 1 "TirePWarn_SoftWarn" 2 "TirePWarn_HardWarn" 3 "TirePWarn_ResdWarn";
VAL_ 104 TirePWarnReRiTirePWarnType 0 "TirePWarnType_NoWarn" 1 "TirePWarnType_iTPMSWarn" 2 "TirePWarnType_dTPMSWarn" 3 "TirePWarnType_FullWarn";
VAL_ 88 PtTqAtWhlsFrntQly 0 "Qly3_De0" 1 "Qly3_De1" 2 "Qly3_De2" 3 "Qly3_De3" 4 "Qly3_De4" 5 "Qly3_De5" 6 "Qly3_De6" 7 "Qly3_De7";
VAL_ 89 PtTqAtWhlsReQly 0 "Qly3_De0" 1 "Qly3_De1" 2 "Qly3_De2" 3 "Qly3_De3" 4 "Qly3_De4" 5 "Qly3_De5" 6 "Qly3_De6" 7 "Qly3_De7";
VAL_ 133 AdSecBrkActvnGroupSafeActvnReq 0 "OnOff1_Off" 1 "OnOff1_On";
VAL_ 133 AdSecBrkActvnGroupSafeDeactvnReq 0 "OnOff1_Off" 1 "OnOff1_On";
VAL_ 352 TirePMonSysFlt 0 "TirePMonSysFlt_NoSysFlt" 1 "TirePMonSysFlt_iTPMSTmpUnvlb" 2 "TirePMonSysFlt_iTPMSSysFlt" 3 "TirePMonSysFlt_dTPMSSysFlt" 4 "TirePMonSysFlt_SysFltTmpUnvlb" 5 "TirePMonSysFlt_CmnSysFlt" 6 "TirePMonSysFlt_resd";
VAL_ 352 TirePValFrntLeTirePabsltValQF 0 "TirePAbsltValQf_Norm" 1 "TirePAbsltValQf_OldVal" 2 "TirePAbsltValQf_UpdVal" 3 "TirePAbsltValQf_SnsrFlt";
VAL_ 352 TirePValFrntLeTirePPosn 0 "TirePPosn_NoPReadingOrPReadingOkWithOutPosn" 1 "TirePPosn_PReadingWithPosn";
VAL_ 352 TirePValFrntRiTirePAbsltValQF 0 "TirePAbsltValQf_Norm" 1 "TirePAbsltValQf_OldVal" 2 "TirePAbsltValQf_UpdVal" 3 "TirePAbsltValQf_SnsrFlt";
VAL_ 352 TirePValFrntRiTirePPosn 0 "TirePPosn_NoPReadingOrPReadingOkWithOutPosn" 1 "TirePPosn_PReadingWithPosn";
VAL_ 352 TirePValReLeTirePAbsltValQF 0 "TirePAbsltValQf_Norm" 1 "TirePAbsltValQf_OldVal" 2 "TirePAbsltValQf_UpdVal" 3 "TirePAbsltValQf_SnsrFlt";
VAL_ 352 TirePValReLeTirePPosn 0 "TirePPosn_NoPReadingOrPReadingOkWithOutPosn" 1 "TirePPosn_PReadingWithPosn";
VAL_ 352 TirePValReRiTirePAbsltValQF 0 "TirePAbsltValQf_Norm" 1 "TirePAbsltValQf_OldVal" 2 "TirePAbsltValQf_UpdVal" 3 "TirePAbsltValQf_SnsrFlt";
VAL_ 352 TirePValReRiTirePPosn 0 "TirePPosn_NoPReadingOrPReadingOkWithOutPosn" 1 "TirePPosn_PReadingWithPosn";
VAL_ 352 TirePWarnCmnTirePWarn 0 "TirePWarn_NoWarn" 1 "TirePWarn_SoftWarn" 2 "TirePWarn_HardWarn" 3 "TirePWarn_ResdWarn";
VAL_ 352 TirePWarnCmnTirePWarnType 0 "TirePWarnType_NoWarn" 1 "TirePWarnType_iTPMSWarn" 2 "TirePWarnType_dTPMSWarn" 3 "TirePWarnType_FullWarn";
VAL_ 352 TirePWarnFrntLeTirePWarn 0 "TirePWarn_NoWarn" 1 "TirePWarn_SoftWarn" 2 "TirePWarn_HardWarn" 3 "TirePWarn_ResdWarn";
VAL_ 352 TirePWarnFrntLeTirePWarnType 0 "TirePWarnType_NoWarn" 1 "TirePWarnType_iTPMSWarn" 2 "TirePWarnType_dTPMSWarn" 3 "TirePWarnType_FullWarn";
VAL_ 120 PrimSteerMotTqSteerMotTqQf 0 "GenQf1_UndefindDataAccur" 1 "GenQf1_TmpUndefdData" 2 "GenQf1_DataAccurNotWithinSpcn" 3 "GenQf1_AccurData";
VAL_ 391 DrvrIntvStsDrvrIntvByAccrPedl 0 "NoYes1_No" 1 "NoYes1_Yes";
VAL_ 391 DrvrIntvStsDrvrIntvByBrkPedl 0 "NoYes1_No" 1 "NoYes1_Yes";
VAL_ 391 DrvrIntvStsDrvrIntvBySteering 0 "NoYes1_No" 1 "NoYes1_Yes";
VAL_ 391 DrvrPrsnt 0 "NoYesCrit1_NotVld1" 1 "NoYesCrit1_No" 2 "NoYesCrit1_Yes" 3 "NoYesCrit1_NotVld2";
VAL_ 391 DrvrPrsntQf 0 "Qf1_DevOfDataUndefd" 1 "Qf1_DataTmpUndefdAndEvlnInProgs" 2 "Qf1_DevOfDataNotWithinRngAllwd" 3 "Qf1_DataCalcdWithDevDefd";
VAL_ 1136 AsySftyEnaDecel 0 "OnOff1_Off" 1 "OnOff1_On";
VAL_ 917 ChrgnTypExt 0 "ChrgnTyp_Disconnected" 1 "ChrgnTyp_AcChrgn" 2 "ChrgnTyp_ChaChrgn" 3 "ChrgnTyp_CcsChrgn" 4 "ChrgnTyp_GbtChrgn" 5 "ChrgnTyp_ThreePhaChrgn" 6 "ChrgnTyp_Indu" 255 "ChrgnTyp_Invld";
VAL_ 917 ChrgrHndlStsExt 0 "OnBdChrgrHndlSts_Disconnected" 1 "OnBdChrgrHndlSts_ConnectedWithoutPower" 2 "OnBdChrgrHndlSts_PowerAvailableButNotActivated" 3 "OnBdChrgrHndlSts_ConnectedWithPower" 4 "OnBdChrgrHndlSts_Init" 5 "OnBdChrgrHndlSts_Fault";
VAL_ 83 AutnmsDrvModMngtExtSafeAutnmsDrvModSts1 0 "ActvSt_Idle" 1 "ActvSt_Actv" 2 "ActvSt_NotActv";
VAL_ 83 AutnmsDrvModMngtExtSafeVehOperModSts1 0 "VehOperModSts1_Ukwn" 1 "VehOperModSts1_NoVehOper" 2 "VehOperModSts1_VehOper";
VAL_ 83 VehManDeactvnReqInProgs1 0 "VehManDeactvnReqInProgs_NoReq" 1 "VehManDeactvnReqInProgs_BgnStopReq" 2 "VehManDeactvnReqInProgs_StopReqd" 3 "VehManDeactvnReqInProgs_Resd";
VAL_ 83 VehUsgSt 0 "ExtModSts_NoMod" 1 "ExtModSts_IniMod" 2 "ExtModSts_ClimaMod" 3 "ExtModSts_RadioMod" 4 "ExtModSts_SrvMod" 5 "ExtModSts_PrpsnActvMod";
VAL_ 131 VehOpReqInVehDynGroupSafeVehOpReq 0 "VehOpReq_NoReq" 1 "VehOpReq_ReqNVOmod" 2 "VehOpReq_ReqVOmod";
VAL_ 1104 CornrStfnCornrStfnQly 0 "Qly2_Flt" 1 "Qly2_NoInfo" 2 "Qly2_Vld";
VAL_ 1104 HvBattLimnExt 0 "ThermWarn_OK" 1 "ThermWarn_PreWarn" 2 "ThermWarn_ThermWarn";
VAL_ 1104 LgtStfnLgtStfnQly 0 "Qly2_Flt" 1 "Qly2_NoInfo" 2 "Qly2_Vld";
VAL_ 97 StandStillMgrStsForHldSafeStandStillSts 0 "VehHldSts1_NotActv" 1 "VehHldSts1_SoftStop" 2 "VehHldSts1_DrvrOffRels" 3 "VehHldSts1_HldActv" 4 "VehHldSts1_Resd";
VAL_ 97 SwtBeamHiToAPI 0 "BeamHiFctReq1_Neut" 1 "BeamHiFctReq1_Flash" 2 "BeamHiFctReq1_HiBeam" 3 "BeamHiFctReq1_LoBeam";
VAL_ 97 SwtIndcrToAPIIndcrTypExtReq 0 "IndcrTypExt1_Off" 1 "IndcrTypExt1_Le" 2 "IndcrTypExt1_Ri";
VAL_ 97 SwtIndcrToAPIIndcrTypExtReqToUpdQf 0 "Qf1_DevOfDataUndefd" 1 "Qf1_DataTmpUndefdAndEvlnInProgs" 2 "Qf1_DevOfDataNotWithinRngAllwd" 3 "Qf1_DataCalcdWithDevDefd";
VAL_ 97 SwtLiHzrdWarnToAPI 0 "PsdNotPsd_NotPsd" 1 "PsdNotPsd_Psd";
VAL_ 1092 AplidSwtExtrLiToAPILiExtFctQf 0 "Qf1_DevOfDataUndefd" 1 "Qf1_DataTmpUndefdAndEvlnInProgs" 2 "Qf1_DevOfDataNotWithinRngAllwd" 3 "Qf1_DataCalcdWithDevDefd";
VAL_ 1092 AplidSwtExtrLiToAPILiExtFctReq1 0 "LiExtFctReq1_Off" 1 "LiExtFctReq1_Pos" 2 "LiExtFctReq1_Lo" 3 "LiExtFctReq1_AutLi";
VAL_ 148 WhlLockStsDegradedSts 0 "WhlLockDegraded1_Ukwn" 1 "WhlLockDegraded1_FullFcn" 2 "WhlLockDegraded1_DegradedFcn" 3 "WhlLockDegraded1_NoFcn";
VAL_ 148 WhlLockStsLockSts 0 "WhlLockSts1_Ukwn" 1 "WhlLockSts1_AllWhlsReld" 2 "WhlLockSts1_FrntWhlsLockd" 3 "WhlLockSts1_ReWhlsLockd" 4 "WhlLockSts1_AllWhlsLockd";
VAL_ 84 HornActvnReqIf 0 "OnOff1_Off" 1 "OnOff1_On";
VAL_ 84 HvSysActvReqExt 0 "Boolean_FALSE" 1 "Boolean_TRUE";
VAL_ 84 RainSnsrCmdIf 0 "RainSnsrCmd1_RainSnsrBtnNotPush" 1 "RainSnsrCmd1_RainSnsrBtnPush";
VAL_ 84 SnsrClngReqIfClngProg 0 "ClngProg_Off" 1 "ClngProg_Prog1" 2 "ClngProg_Prog2" 3 "ClngProg_Prog3" 4 "ClngProg_Prog4" 5 "ClngProg_Prog5" 6 "ClngProg_Prog6" 7 "ClngProg_Prog7" 8 "ClngProg_Prog8" 9 "ClngProg_Prog9" 10 "ClngProg_Prog10" 11 "ClngProg_Prog11" 12 "ClngProg_Prog12" 13 "ClngProg_Prog13" 14 "ClngProg_Prog14" 15 "ClngProg_AbortClng";
VAL_ 84 SnsrClngReqIfSnsrSeld 0 "SnsrSeld_Off" 1 "SnsrSeld_Lidar" 2 "SnsrSeld_RoofMntd" 3 "SnsrSeld_SurrndgsCamFrnt" 4 "SnsrSeld_SurrndgsCamRe" 5 "SnsrSeld_SurrndgsCamSideLe" 6 "SnsrSeld_SurrndgsCamSideRi" 7 "SnsrSeld_SurrndgsCamWindScr1" 8 "SnsrSeld_SurrndgsCamWindScr2" 9 "SnsrSeld_Rsvd1" 10 "SnsrSeld_Rsvd2" 11 "SnsrSeld_Rsvd3" 12 "SnsrSeld_Rsvd4" 13 "SnsrSeld_Rsvd5" 14 "SnsrSeld_Rsvd6" 15 "SnsrSeld_Rsvd7";
VAL_ 84 SwtBeamHiFromAPI 0 "BeamHiFctReq1_Neut" 1 "BeamHiFctReq1_Flash" 2 "BeamHiFctReq1_HiBeam" 3 "BeamHiFctReq1_LoBeam";
VAL_ 84 WinWshngCmdIf 0 "WinWshngCmdIf_WinWshrOff" 1 "WinWshngCmdIf_FrntWshrCmd" 2 "WinWshngCmdIf_ReWshrCmd";
VAL_ 84 WipgSpdIntlIf 0 "WipgSpdIntlFromHmi_Posn0" 1 "WipgSpdIntlFromHmi_Posn1" 2 "WipgSpdIntlFromHmi_Posn2" 3 "WipgSpdIntlFromHmi_Posn3" 4 "WipgSpdIntlFromHmi_Posn4" 5 "WipgSpdIntlFromHmi_Posn5" 6 "WipgSpdIntlFromHmi_Posn6" 7 "WipgSpdIntlFromHmi_Posn7";
VAL_ 84 WiprFrntReqIfFrntWiprLvrCmd1 0 "FrntWiprLvrCmd1_FrntWiprOff" 1 "FrntWiprLvrCmd1_FrntWiprSngStk" 2 "FrntWiprLvrCmd1_FrntWiprIntm" 3 "FrntWiprLvrCmd1_FrntWiprContnsLoSpd" 4 "FrntWiprLvrCmd1_FrntWiprContnsHiSpd";
VAL_ 84 WiprFrntReqIfFrntWiprLvrQf 0 "Qf1_DevOfDataUndefd" 1 "Qf1_DataTmpUndefdAndEvlnInProgs" 2 "Qf1_DevOfDataNotWithinRngAllwd" 3 "Qf1_DataCalcdWithDevDefd";
VAL_ 84 WiprReCmdIf 0 "WiprReCmdIf_ReWiperRotyOff" 1 "WiprReCmdIf_ReWiprRotySng" 2 "WiprReCmdIf_ReWiprRotyIntm" 3 "WiprReCmdIf_ReWiprRotyContns";
VAL_ 297 CnvincAPIEna 0 "CnvincAPIEna_Undefd" 1 "CnvincAPIEna_NoReq" 2 "CnvincAPIEna_Req";
VAL_ 297 OkToClsDoorOkToClsDoorDrvr 0 "OkToClsDoor_NOK" 1 "OkToClsDoor_OK";
VAL_ 297 OkToClsDoorOkToClsDoorDrvrRe 0 "OkToClsDoor_NOK" 1 "OkToClsDoor_OK";
VAL_ 297 OkToClsDoorOkToClsDoorPass 0 "OkToClsDoor_NOK" 1 "OkToClsDoor_OK";
VAL_ 297 OkToClsDoorOkToClsDoorPassRe 0 "OkToClsDoor_NOK" 1 "OkToClsDoor_OK";
VAL_ 297 OkToOpenDoorOkToOpenDoorDrvr 0 "OkToOpenDoor_NOK" 1 "OkToOpenDoor_OKToSlightlyOpen" 2 "OkToOpenDoor_OK";
VAL_ 297 OkToOpenDoorOkToOpenDoorDrvrRe 0 "OkToOpenDoor_NOK" 1 "OkToOpenDoor_OKToSlightlyOpen" 2 "OkToOpenDoor_OK";
VAL_ 297 OkToOpenDoorOkToOpenDoorPass 0 "OkToOpenDoor_NOK" 1 "OkToOpenDoor_OKToSlightlyOpen" 2 "OkToOpenDoor_OK";
VAL_ 297 OkToOpenDoorOkToOpenDoorPassRe 0 "OkToOpenDoor_NOK" 1 "OkToOpenDoor_OKToSlightlyOpen" 2 "OkToOpenDoor_OK";
VAL_ 296 PwrDoorDrvrClsReqAPI 0 "DoorClsReq_Idle" 1 "DoorClsReq_Open" 2 "DoorClsReq_Close" 3 "DoorClsReq_Stop";
VAL_ 296 PwrDoorDrvrReClsReqAPI 0 "DoorClsReq_Idle" 1 "DoorClsReq_Open" 2 "DoorClsReq_Close" 3 "DoorClsReq_Stop";
VAL_ 296 PwrDoorPassClsReqAPI 0 "DoorClsReq_Idle" 1 "DoorClsReq_Open" 2 "DoorClsReq_Close" 3 "DoorClsReq_Stop";
VAL_ 296 PwrDoorPassReClsReqAPI 0 "DoorClsReq_Idle" 1 "DoorClsReq_Open" 2 "DoorClsReq_Close" 3 "DoorClsReq_Stop";
VAL_ 260 HmiAutnmsStsHmiAutnmsSts 0 "HmiAutnmsSts1_Ukwn" 1 "HmiAutnmsSts1_Off" 2 "HmiAutnmsSts1_NotReady" 3 "HmiAutnmsSts1_Ready" 4 "HmiAutnmsSts1_On" 5 "HmiAutnmsSts1_Flt" 6 "HmiAutnmsSts1_rsd1" 7 "HmiAutnmsSts1_rsd2";
VAL_ 35 ExtDcDcActvnSts2 0 "Boolean_FALSE" 1 "Boolean_TRUE";
VAL_ 40 ExtDcDcActvnSts 0 "Boolean_FALSE" 1 "Boolean_TRUE";
VAL_ 46 AutnmsDrvStReqAutnmsDrvStReq 0 "ActvSt_Idle" 1 "ActvSt_Actv" 2 "ActvSt_NotActv";
VAL_ 293 VehOperStReqVehOperStReq 0 "VehOpReq_NoReq" 1 "VehOpReq_ReqNVOmod" 2 "VehOpReq_ReqVOmod";
VAL_ 135 AdDirReqDirReq 0 "AsyDesDir1_NoReq" 1 "AsyDesDir1_Fwd" 2 "AsyDesDir1_Rvs" 3 "AsyDesDir1_ZeroTorque";
VAL_ 135 AdStandStillReqReq 0 "NoReqHoldRels1_NoReq" 1 "NoReqHoldRels1_Hld" 2 "NoReqHoldRels1_Rels" 3 "NoReqHoldRels1_Resd";
VAL_ 135 VehUsgStReq 0 "ExtModSts_NoMod" 1 "ExtModSts_IniMod" 2 "ExtModSts_ClimaMod" 3 "ExtModSts_RadioMod" 4 "ExtModSts_SrvMod" 5 "ExtModSts_PrpsnActvMod";
VAL_ 280 PrimRoadGradientFromAdBankingConf 0 "Qly3_De0" 1 "Qly3_De1" 2 "Qly3_De2" 3 "Qly3_De3" 4 "Qly3_De4" 5 "Qly3_De5" 6 "Qly3_De6" 7 "Qly3_De7";
VAL_ 280 PrimRoadGradientFromAdInclnConf 0 "Qly3_De0" 1 "Qly3_De1" 2 "Qly3_De2" 3 "Qly3_De3" 4 "Qly3_De4" 5 "Qly3_De5" 6 "Qly3_De6" 7 "Qly3_De7";
VAL_ 288 AdFusedFricEstimnFricEstimnConf 0 "Qly3_De0" 1 "Qly3_De1" 2 "Qly3_De2" 3 "Qly3_De3" 4 "Qly3_De4" 5 "Qly3_De5" 6 "Qly3_De6" 7 "Qly3_De7";
VAL_ 288 AdpLiReqFromAPIAhbcActvn 0 "AdpActrActvnReq1_NoReq" 1 "AdpActrActvnReq1_Req";
VAL_ 288 AdpLiReqFromAPIHzrdLiActvnReq 0 "AdpActrActvnReq1_NoReq" 1 "AdpActrActvnReq1_Req";
VAL_ 288 AdpLiReqFromAPIHzrdLiDeactnReq 0 "AdpActrActvnReq1_NoReq" 1 "AdpActrActvnReq1_Req";
VAL_ 288 AdpLiReqFromAPIIncrLiRiReq 0 "AdpActrActvnReq1_NoReq" 1 "AdpActrActvnReq1_Req";
VAL_ 288 AdpLiReqFromAPIIndcrLeReq 0 "AdpActrActvnReq1_NoReq" 1 "AdpActrActvnReq1_Req";
VAL_ 288 SwtExtrLiFromAPILiExtFctQf 0 "Qf1_DevOfDataUndefd" 1 "Qf1_DataTmpUndefdAndEvlnInProgs" 2 "Qf1_DevOfDataNotWithinRngAllwd" 3 "Qf1_DataCalcdWithDevDefd";
VAL_ 288 SwtExtrLiFromAPILiExtFctReq1 0 "LiExtFctReq1_Off" 1 "LiExtFctReq1_Pos" 2 "LiExtFctReq1_Lo" 3 "LiExtFctReq1_AutLi";
VAL_ 1091 ActvnOfHndlDoorLiFromAPIHndlDoorLiDrvr 0 "OnOff1_Off" 1 "OnOff1_On";
VAL_ 1091 ActvnOfHndlDoorLiFromAPIHndlDoorLiDrvrRe 0 "OnOff1_Off" 1 "OnOff1_On";
VAL_ 1091 ActvnOfHndlDoorLiFromAPIHndlDoorLiPass 0 "OnOff1_Off" 1 "OnOff1_On";
VAL_ 1091 ActvnOfHndlDoorLiFromAPIHndlDoorLiPassRe 0 "OnOff1_Off" 1 "OnOff1_On";
VAL_ 150 AdWhlLockReqNoReqApplyRel 0 "NoReqApplyRels1_NoReq" 1 "NoReqApplyRels1_Apply" 2 "NoReqApplyRels1_Rels";
SIG_GROUP_ 119 AccrPedlPsd 1 : AccrPedlPsdAccrPedlPsd AccrPedlPsdAccrPedlPsdChks AccrPedlPsdAccrPedlPsdCntr AccrPedlPsdAccrPedlPsdSts;
SIG_GROUP_ 1091 ActvnOfHndlDoorLiFromAPI 1 : ActvnOfHndlDoorLiFromAPIHndlDoorLiDrvr ActvnOfHndlDoorLiFromAPIHndlDoorLiDrvrRe ActvnOfHndlDoorLiFromAPIHndlDoorLiPass ActvnOfHndlDoorLiFromAPIHndlDoorLiPassRe;
SIG_GROUP_ 135 AdDirReq 1 : AdDirReqChks AdDirReqCntr AdDirReqDirReq;
SIG_GROUP_ 150 AdFreeDst 1 : AdFreeDstChks AdFreeDstCntr AdFreeDstFreeDstFwd AdFreeDstFreeDstRvs;
SIG_GROUP_ 288 AdFusedFricEstimn 1 : AdFusedFricEstimnFricEstimn AdFusedFricEstimnFricEstimnConf;
SIG_GROUP_ 86 AdNomALgtReqGroupSafe 1 : AdNomALgtReqGroupSafeALgtNomReqMax AdNomALgtReqGroupSafeALgtNomReqMin AdNomALgtReqGroupSafeChks AdNomALgtReqGroupSafeCntr AdNomALgtReqGroupSafeNegLimForJerk AdNomALgtReqGroupSafePosLimForJerk;
SIG_GROUP_ 288 AdpLiReqFromAPI 1 : AdpLiReqFromAPIAhbcActvn AdpLiReqFromAPIChks AdpLiReqFromAPICntr AdpLiReqFromAPIHzrdLiActvnReq AdpLiReqFromAPIHzrdLiDeactnReq AdpLiReqFromAPIIncrLiRiReq AdpLiReqFromAPIIndcrLeReq;
SIG_GROUP_ 87 AdPrimALgtLimReqGroupSafe 1 : AdPrimALgtLimReqGroupSafeALgtMaxReq AdPrimALgtLimReqGroupSafeALgtMinReq AdPrimALgtLimReqGroupSafeChks AdPrimALgtLimReqGroupSafeCntr;
SIG_GROUP_ 133 AdSecBrkActvnGroupSafe 1 : AdSecBrkActvnGroupSafeActvnReq AdSecBrkActvnGroupSafeChks AdSecBrkActvnGroupSafeCntr AdSecBrkActvnGroupSafeDeactvnReq;
SIG_GROUP_ 135 AdStandStillReq 1 : AdStandStillReqChks AdStandStillReqCntr AdStandStillReqReq;
SIG_GROUP_ 150 AdWhlLockReq 1 : AdWhlLockReqChks AdWhlLockReqCntr AdWhlLockReqNoReqApplyRel;
SIG_GROUP_ 148 ALgtMaxAvl 1 : ALgtMaxAvlALgtMaxAvl ALgtMaxAvlALgtMaxAvlLong ALgtMaxAvlChks ALgtMaxAvlCntr ALgtMaxAvlDecelLgtMaxAvl;
SIG_GROUP_ 384 ALnchTiDly3 1 : ALnchTiDly3Qf ALnchTiDly3Sec2;
SIG_GROUP_ 384 AlrmSts1 1 : AlrmSt AlrmTrgSrc SnsrInclnFailr SnsrIntrScanrFailr SnsrSoundrBattBackedFailr;
SIG_GROUP_ 1092 AplidSwtExtrLiToAPI 1 : AplidSwtExtrLiToAPILiExtFctCntr AplidSwtExtrLiToAPILiExtFctCrc AplidSwtExtrLiToAPILiExtFctQf AplidSwtExtrLiToAPILiExtFctReq1;
SIG_GROUP_ 83 AutnmsDrvModMngtExtSafe 1 : AutnmsDrvModMngtExtSafeAutnmsDrvModSts1 AutnmsDrvModMngtExtSafeChecksum AutnmsDrvModMngtExtSafeCounter AutnmsDrvModMngtExtSafeVehOperModSts1;
SIG_GROUP_ 46 AutnmsDrvStReq 1 : AutnmsDrvStReqAutnmsDrvStReq AutnmsDrvStReqChecksum AutnmsDrvStReqCounter;
SIG_GROUP_ 1084 BltLockStAtRowSecMid 1 : BltLockStAtRowSecMidForBltLockEquid BltLockStAtRowSecMidForBltLockSt1 BltLockStAtRowSecMidForBltLockSts;
SIG_GROUP_ 83 BrkDegraded 1 : BrkDegradedChks BrkDegradedCntr BrkDegradedSts;
SIG_GROUP_ 133 BrkFricTqTotAtWhlsAct 1 : BrkFricTqTotAtWhlsActBrkFricTqTotAtWhlsAct BrkFricTqTotAtWhlsActBrkFricTqTotAtWhlsActChks BrkFricTqTotAtWhlsActBrkFricTqTotAtWhlsActCntr;
SIG_GROUP_ 119 BrkPedlPsdSafeGroup 1 : BrkPedlNotPsdSafe BrkPedlPsd BrkPedlPsdChks BrkPedlPsdCntr BrkPedlPsdQf;
SIG_GROUP_ 1120 CllsnAidSnvtySeld 1 : CllsnAidSnvtySeldPen CllsnAidSnvtySeldSts;
SIG_GROUP_ 1104 CornrStfn 1 : CornrStfnCornrStfnFrnt CornrStfnCornrStfnQly CornrStfnCornrStfnRe;
SIG_GROUP_ 391 DrvrIntvSts 1 : DrvrIntvStsDrvrIntvByAccrPedl DrvrIntvStsDrvrIntvByBrkPedl DrvrIntvStsDrvrIntvBySteering;
SIG_GROUP_ 391 DrvrPrsntGroup 1 : DrvrPrsnt DrvrPrsntQf DrvrPrsntStsDrvrPrsntChks DrvrPrsntStsDrvrPrsntCntr;
SIG_GROUP_ 260 HmiAutnmsSts 1 : HmiAutnmsStsChecksum HmiAutnmsStsCounter HmiAutnmsStsHmiAutnmsSts;
SIG_GROUP_ 1104 LgtStfn 1 : LgtStfnLgtStfnFrnt LgtStfnLgtStfnQly LgtStfnLgtStfnRe;
SIG_GROUP_ 297 OkToClsDoor 1 : OkToClsDoorOkToClsDoorChks OkToClsDoorOkToClsDoorCntr OkToClsDoorOkToClsDoorDrvr OkToClsDoorOkToClsDoorDrvrRe OkToClsDoorOkToClsDoorPass OkToClsDoorOkToClsDoorPassRe;
SIG_GROUP_ 297 OkToOpenDoor 1 : OkToOpenDoorOkToOpenDoorChks OkToOpenDoorOkToOpenDoorCntr OkToOpenDoorOkToOpenDoorDrvr OkToOpenDoorOkToOpenDoorDrvrRe OkToOpenDoorOkToOpenDoorPass OkToOpenDoorOkToOpenDoorPassRe;
SIG_GROUP_ 119 OvrdDecelByDrvr 1 : OvrdDecelByDrvrOvrdDecelByDrvr OvrdDecelByDrvrOvrdDecelByDrvrChks OvrdDecelByDrvrOvrdDecelByDrvrCntr;
SIG_GROUP_ 280 PrimRoadGradientFromAd 1 : PrimRoadGradientFromAdBanking PrimRoadGradientFromAdBankingConf PrimRoadGradientFromAdChks PrimRoadGradientFromAdCntr PrimRoadGradientFromAdIncln PrimRoadGradientFromAdInclnConf;
SIG_GROUP_ 120 PrimSteerMotTq 1 : PrimSteerMotTqSteerMotTq PrimSteerMotTqSteerMotTqQf;
SIG_GROUP_ 88 PtTqAtWhlFrntActGroup 1 : PtTqAtAxleFrntAct PtTqAtWhlFrntLeAct PtTqAtWhlFrntRiAct PtTqAtWhlsFrntQly;
SIG_GROUP_ 89 PtTqAtWhlReActGroup 1 : PtTqAtAxleReAct PtTqAtWhlReLeAct PtTqAtWhlReRiAct PtTqAtWhlsReQly;
SIG_GROUP_ 512 RoadLoadNom 1 : RoadLoadNomCoeff0 RoadLoadNomCoeff1 RoadLoadNomCoeff2 RoadLoadNomCoeffSts;
SIG_GROUP_ 1136 SftyDecelGroupSafe 1 : AsySftyDecelReq AsySftyEnaDecel SftyDecelGroupSafeChks SftyDecelGroupSafeCntr;
SIG_GROUP_ 84 SnsrClngReqIf 1 : SnsrClngReqIfClngProg SnsrClngReqIfSnsrSeld;
SIG_GROUP_ 97 StandStillMgrStsForHldSafe 1 : StandStillMgrStsForHldSafeChks StandStillMgrStsForHldSafeCntr StandStillMgrStsForHldSafeStandStillSts;
SIG_GROUP_ 288 SwtExtrLiFromAPI 1 : SwtExtrLiFromAPILiExtFctCntr SwtExtrLiFromAPILiExtFctCrc SwtExtrLiFromAPILiExtFctQf SwtExtrLiFromAPILiExtFctReq1;
SIG_GROUP_ 97 SwtIndcrToAPI 1 : SwtIndcrToAPIIndcrTypExtReq SwtIndcrToAPIIndcrTypExtReqChks SwtIndcrToAPIIndcrTypExtReqCntr SwtIndcrToAPIIndcrTypExtReqToUpdQf;
SIG_GROUP_ 352 TirePValFrntLe 1 : TirePValFrntLeTirepabsltVal1 TirePValFrntLeTirePabsltValQF TirePValFrntLeTirePPosn;
SIG_GROUP_ 352 TirePValFrntRi 1 : TirePValFrntRiTirePAbsltVal1 TirePValFrntRiTirePAbsltValQF TirePValFrntRiTirePPosn;
SIG_GROUP_ 352 TirePValReLe 1 : TirePValReLeTirePAbsltVal1 TirePValReLeTirePAbsltValQF TirePValReLeTirePPosn;
SIG_GROUP_ 352 TirePValReRi 1 : TirePValReRiTirePAbsltVal1 TirePValReRiTirePAbsltValQF TirePValReRiTirePPosn;
SIG_GROUP_ 352 TirePWarnCmn 1 : TirePWarnCmnTirePWarn TirePWarnCmnTirePWarnType;
SIG_GROUP_ 352 TirePWarnFrntLe 1 : TirePWarnFrntLeTirePWarn TirePWarnFrntLeTirePWarnType;
SIG_GROUP_ 104 TirePWarnFrntRi 1 : TirePWarnFrntRiTirePWarn TirePWarnFrntRiTirePWarnType;
SIG_GROUP_ 104 TirePWarnReLe 1 : TirePWarnReLeTirePWarn TirePWarnReLeTirePWarnType;
SIG_GROUP_ 104 TirePWarnReRi 1 : TirePWarnReRiTirePWarn TirePWarnReRiTirePWarnType;
SIG_GROUP_ 311 TireRdEstimdAtWhls 1 : TireRdEstimdAtWhlsFrLe TireRdEstimdAtWhlsFrRi TireRdEstimdAtWhlsReLe TireRdEstimdAtWhlsReRi;
SIG_GROUP_ 293 VehOperStReq 1 : VehOperStReqChecksum VehOperStReqCounter VehOperStReqVehOperStReq;
SIG_GROUP_ 131 VehOpReqInVehDynGroupSafe 1 : VehOpReqInVehDynGroupSafeChks VehOpReqInVehDynGroupSafeCntr VehOpReqInVehDynGroupSafeVehOpReq;
SIG_GROUP_ 148 WhlLockSts 1 : WhlLockStsChks WhlLockStsCntr WhlLockStsDegradedSts WhlLockStsLockSts;
SIG_GROUP_ 84 WiprFrntReqIf 1 : WiprFrntReqIfFrntWiprLvrCmd1 WiprFrntReqIfFrntWiprLvrCntr WiprFrntReqIfFrntWiprLvrCrc WiprFrntReqIfFrntWiprLvrQf;
